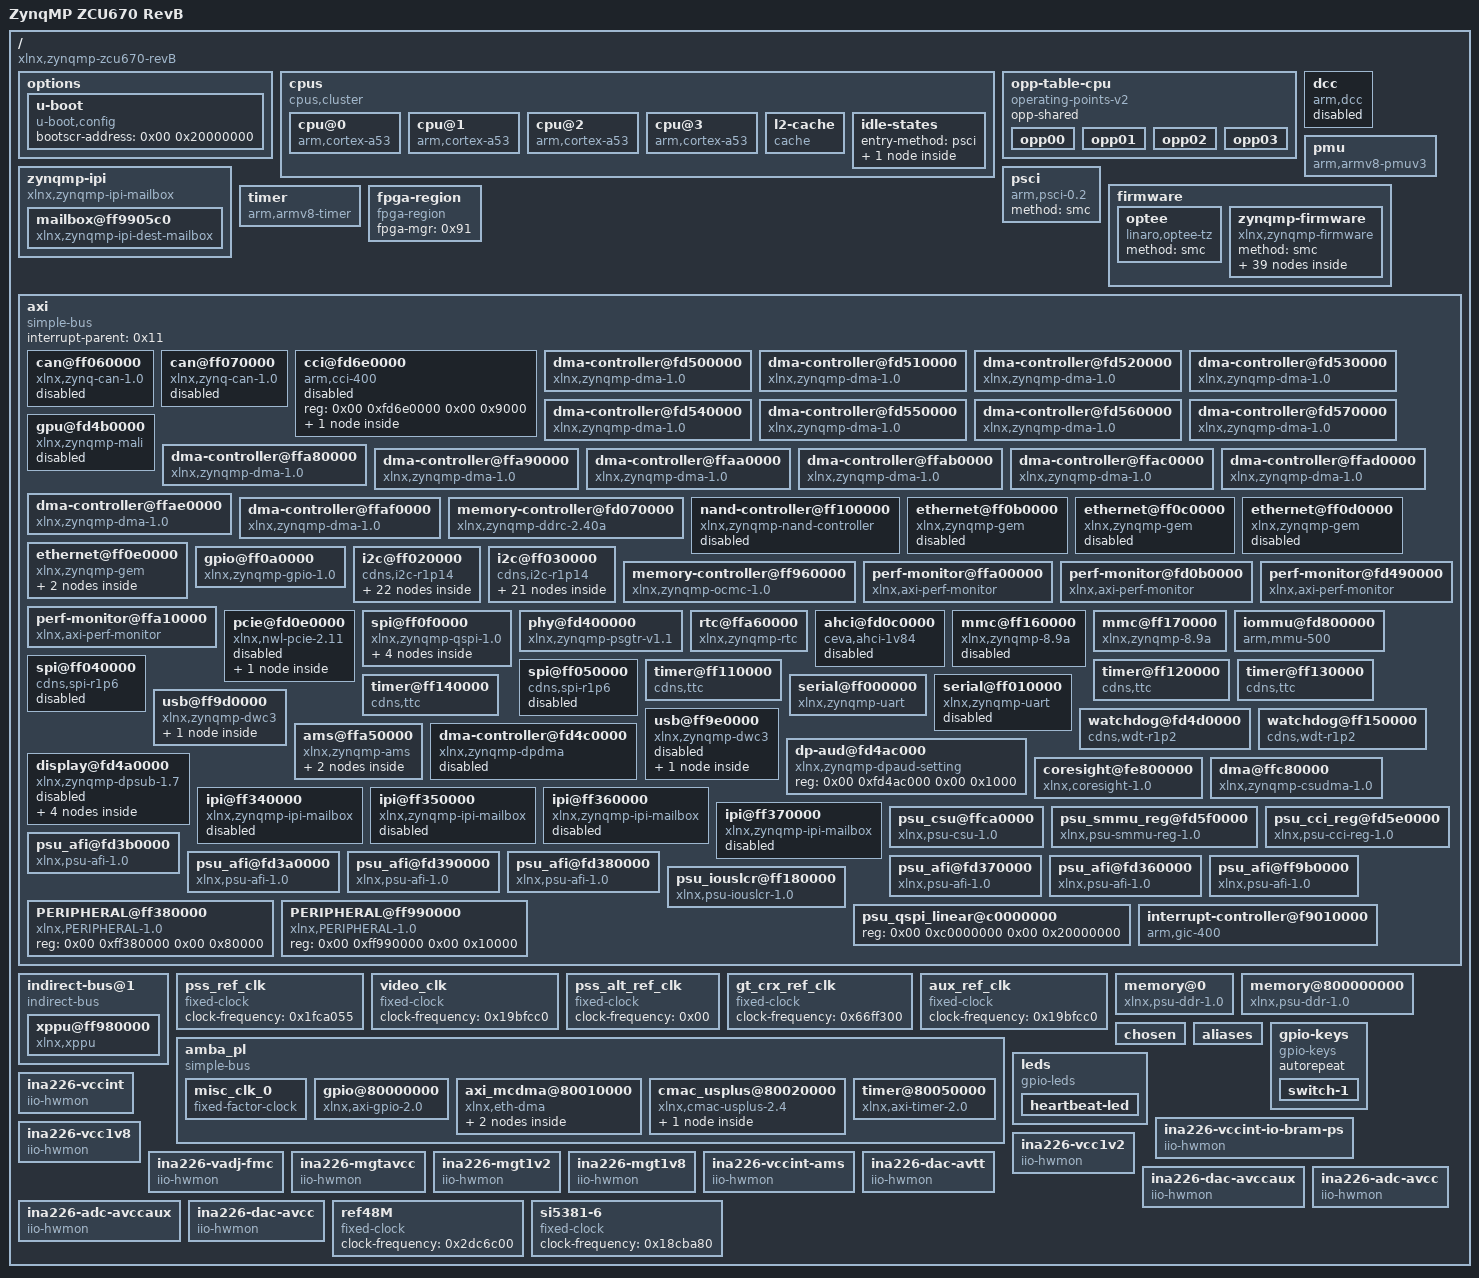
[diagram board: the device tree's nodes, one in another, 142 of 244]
/dts-v1/;

/ {
	compatible = "xlnx,zynqmp-zcu670-revB\0xlnx,zynqmp-zcu670\0xlnx,zynqmp";
	#address-cells = <0x02>;
	#size-cells = <0x02>;
	model = "ZynqMP ZCU670 RevB";
	board = "zcu670";
	device_id = "xczu67dr";
	slrcount = <0x01>;
	family = "ZynqMP";

	options {

		u-boot {
			compatible = "u-boot,config";
			bootscr-address = <0x00 0x20000000>;
		};
	};

	cpus {
		#address-cells = <0x01>;
		#size-cells = <0x00>;
		compatible = "cpus,cluster";
		#ranges-address-cells = <0x02>;
		#ranges-size-cells = <0x02>;
		phandle = <0xb0>;

		cpu@0 {
			compatible = "arm,cortex-a53";
			device_type = "cpu";
			enable-method = "psci";
			operating-points-v2 = <0x6f>;
			reg = <0x00>;
			cpu-idle-states = <0x70>;
			next-level-cache = <0x71>;
			clocks = <0x72 0x0a>;
			xlnx,psu-ep = <0x01>;
			xlnx,pss-video-ref-clk-freq = <0x1fc9f08>;
			xlnx,ip-name = "psu_cortexa53";
			xlnx,cpu-1x-clk-freq-hz = <0x00>;
			xlnx,psu-silicon-version = <0x03>;
			cpu-frequency = <0x47865d45>;
			xlnx,cpu-clk-freq-hz = <0x47865d45>;
			xlnx,pss-gt-ref-clk-freq = <0x1fc9f08>;
			xlnx,pss-ref-clk-freq = <0x1fc9f08>;
			bus-handle = <0x01>;
			xlnx,pss-aux-ref-clk-freq = <0x1fc9f08>;
			xlnx,psu-device = "PS8a";
			xlnx,timestamp-clk-freq = <0x5f5dd19>;
			stamp-frequency = <0x5f5dd19>;
			xlnx,pss-alt-ref-clk-freq = <0x1fc9f08>;
			phandle = <0x87>;
		};

		cpu@1 {
			compatible = "arm,cortex-a53";
			device_type = "cpu";
			enable-method = "psci";
			reg = <0x01>;
			operating-points-v2 = <0x6f>;
			cpu-idle-states = <0x70>;
			next-level-cache = <0x71>;
			xlnx,psu-ep = <0x01>;
			xlnx,ip-name = "psu_cortexa53";
			xlnx,cpu-1x-clk-freq-hz = <0x00>;
			cpu-frequency = <0x47865d45>;
			xlnx,cpu-clk-freq-hz = <0x47865d45>;
			xlnx,psu-silicon-version = <0x03>;
			xlnx,pss-ref-clk-freq = <0x1fc9f08>;
			bus-handle = <0x01>;
			xlnx,psu-device = "PS8a";
			stamp-frequency = <0x5f5dd19>;
			xlnx,timestamp-clk-freq = <0x5f5dd19>;
			phandle = <0x88>;
		};

		cpu@2 {
			compatible = "arm,cortex-a53";
			device_type = "cpu";
			enable-method = "psci";
			reg = <0x02>;
			operating-points-v2 = <0x6f>;
			cpu-idle-states = <0x70>;
			next-level-cache = <0x71>;
			xlnx,psu-ep = <0x01>;
			xlnx,ip-name = "psu_cortexa53";
			xlnx,cpu-1x-clk-freq-hz = <0x00>;
			cpu-frequency = <0x47865d45>;
			xlnx,cpu-clk-freq-hz = <0x47865d45>;
			xlnx,psu-silicon-version = <0x03>;
			xlnx,pss-ref-clk-freq = <0x1fc9f08>;
			bus-handle = <0x01>;
			xlnx,psu-device = "PS8a";
			stamp-frequency = <0x5f5dd19>;
			xlnx,timestamp-clk-freq = <0x5f5dd19>;
			phandle = <0x89>;
		};

		cpu@3 {
			compatible = "arm,cortex-a53";
			device_type = "cpu";
			enable-method = "psci";
			reg = <0x03>;
			operating-points-v2 = <0x6f>;
			cpu-idle-states = <0x70>;
			next-level-cache = <0x71>;
			xlnx,psu-ep = <0x01>;
			xlnx,ip-name = "psu_cortexa53";
			xlnx,cpu-1x-clk-freq-hz = <0x00>;
			cpu-frequency = <0x47865d45>;
			xlnx,cpu-clk-freq-hz = <0x47865d45>;
			xlnx,psu-silicon-version = <0x03>;
			xlnx,pss-ref-clk-freq = <0x1fc9f08>;
			bus-handle = <0x01>;
			xlnx,psu-device = "PS8a";
			stamp-frequency = <0x5f5dd19>;
			xlnx,timestamp-clk-freq = <0x5f5dd19>;
			phandle = <0x8a>;
		};

		l2-cache {
			compatible = "cache";
			cache-level = <0x02>;
			cache-unified;
			phandle = <0x71>;
		};

		idle-states {
			entry-method = "psci";

			cpu-sleep-0 {
				compatible = "arm,idle-state";
				arm,psci-suspend-param = <0x40000000>;
				local-timer-stop;
				entry-latency-us = <0x12c>;
				exit-latency-us = <0x258>;
				min-residency-us = <0x2710>;
				phandle = <0x70>;
			};
		};
	};

	opp-table-cpu {
		compatible = "operating-points-v2";
		opp-shared;
		phandle = <0x6f>;

		opp00 {
			opp-hz = <0x00 0x47868bf4>;
			opp-microvolt = <0xf4240>;
			clock-latency-ns = <0x7a120>;
		};

		opp01 {
			opp-hz = <0x00 0x23c345fa>;
			opp-microvolt = <0xf4240>;
			clock-latency-ns = <0x7a120>;
		};

		opp02 {
			opp-hz = <0x00 0x17d783fc>;
			opp-microvolt = <0xf4240>;
			clock-latency-ns = <0x7a120>;
		};

		opp03 {
			opp-hz = <0x00 0x11e1a2fd>;
			opp-microvolt = <0xf4240>;
			clock-latency-ns = <0x7a120>;
		};
	};

	zynqmp-ipi {
		bootph-all;
		compatible = "xlnx,zynqmp-ipi-mailbox";
		interrupt-parent = <0x11>;
		interrupts = <0x00 0x23 0x04>;
		xlnx,ipi-id = <0x00>;
		#address-cells = <0x02>;
		#size-cells = <0x02>;
		ranges;
		phandle = <0xb7>;

		mailbox@ff9905c0 {
			bootph-all;
			compatible = "xlnx,zynqmp-ipi-dest-mailbox";
			reg = <0x00 0xff9905c0 0x00 0x20 0x00 0xff9905e0 0x00 0x20 0x00 0xff990e80 0x00 0x20 0x00 0xff990ea0 0x00 0x20>;
			reg-names = "local_request_region\0local_response_region\0remote_request_region\0remote_response_region";
			#mbox-cells = <0x01>;
			xlnx,ipi-id = <0x04>;
			phandle = <0x8b>;
		};
	};

	dcc {
		compatible = "arm,dcc";
		status = "disabled";
		bootph-all;
		phandle = <0xb8>;
	};

	pmu {
		compatible = "arm,armv8-pmuv3";
		interrupt-parent = <0x11>;
		interrupts = <0x00 0x8f 0x04 0x00 0x90 0x04 0x00 0x91 0x04 0x00 0x92 0x04>;
		interrupt-affinity = <0x87 0x88 0x89 0x8a>;
	};

	psci {
		compatible = "arm,psci-0.2";
		method = "smc";
	};

	firmware {

		optee {
			compatible = "linaro,optee-tz";
			method = "smc";
			phandle = <0xb9>;
		};

		zynqmp-firmware {
			compatible = "xlnx,zynqmp-firmware";
			#power-domain-cells = <0x01>;
			method = "smc";
			bootph-all;
			phandle = <0x7b>;

			power-management {
				bootph-all;
				compatible = "xlnx,zynqmp-power";
				interrupt-parent = <0x11>;
				interrupts = <0x00 0x23 0x04>;
				mboxes = <0x8b 0x00 0x8b 0x01>;
				mbox-names = "tx\0rx";
				phandle = <0xba>;
			};

			soc-nvmem {
				compatible = "xlnx,zynqmp-nvmem-fw";

				nvmem-layout {
					compatible = "fixed-layout";
					#address-cells = <0x01>;
					#size-cells = <0x01>;

					soc-revision@0 {
						reg = <0x00 0x04>;
						phandle = <0xbb>;
					};

					efuse-dna@c {
						reg = <0x0c 0x0c>;
						phandle = <0xbc>;
					};

					efuse-usr0@20 {
						reg = <0x20 0x04>;
						phandle = <0xbd>;
					};

					efuse-usr1@24 {
						reg = <0x24 0x04>;
						phandle = <0xbe>;
					};

					efuse-usr2@28 {
						reg = <0x28 0x04>;
						phandle = <0xbf>;
					};

					efuse-usr3@2c {
						reg = <0x2c 0x04>;
						phandle = <0xc0>;
					};

					efuse-usr4@30 {
						reg = <0x30 0x04>;
						phandle = <0xc1>;
					};

					efuse-usr5@34 {
						reg = <0x34 0x04>;
						phandle = <0xc2>;
					};

					efuse-usr6@38 {
						reg = <0x38 0x04>;
						phandle = <0xc3>;
					};

					efuse-usr7@3c {
						reg = <0x3c 0x04>;
						phandle = <0xc4>;
					};

					efuse-miscusr@40 {
						reg = <0x40 0x04>;
						phandle = <0xc5>;
					};

					efuse-chash@50 {
						reg = <0x50 0x04>;
						phandle = <0xc6>;
					};

					efuse-pufmisc@54 {
						reg = <0x54 0x04>;
						phandle = <0xc7>;
					};

					efuse-sec@58 {
						reg = <0x58 0x04>;
						phandle = <0xc8>;
					};

					efuse-spkid@5c {
						reg = <0x5c 0x04>;
						phandle = <0xc9>;
					};

					efuse-aeskey@60 {
						reg = <0x60 0x20>;
						phandle = <0xca>;
					};

					efuse-ppk0hash@a0 {
						reg = <0xa0 0x30>;
						phandle = <0xcb>;
					};

					efuse-ppk1hash@d0 {
						reg = <0xd0 0x30>;
						phandle = <0xcc>;
					};

					efuse-pufuser@100 {
						reg = <0x100 0x7f>;
						phandle = <0xcd>;
					};
				};
			};

			pcap {
				compatible = "xlnx,zynqmp-pcap-fpga";
				phandle = <0x91>;
			};

			reset-controller {
				compatible = "xlnx,zynqmp-reset";
				#reset-cells = <0x01>;
				status = "okay";
				phandle = <0x03>;
			};

			pinctrl {
				compatible = "xlnx,zynqmp-pinctrl";
				status = "okay";
				phandle = <0x04>;

				i2c0-default {
					phandle = <0x94>;

					mux {
						groups = "i2c0_3_grp";
						function = "i2c0";
					};

					conf {
						groups = "i2c0_3_grp";
						bias-pull-up;
						slew-rate = <0x01>;
						power-source = <0x01>;
					};
				};

				i2c0-gpio-grp {
					phandle = <0x95>;

					mux {
						groups = "gpio0_14_grp\0gpio0_15_grp";
						function = "gpio0";
					};

					conf {
						groups = "gpio0_14_grp\0gpio0_15_grp";
						slew-rate = <0x01>;
						power-source = <0x01>;
					};
				};

				i2c1-default {
					phandle = <0x96>;

					mux {
						groups = "i2c1_4_grp";
						function = "i2c1";
					};

					conf {
						groups = "i2c1_4_grp";
						bias-pull-up;
						slew-rate = <0x01>;
						power-source = <0x01>;
					};
				};

				i2c1-gpio-grp {
					phandle = <0x97>;

					mux {
						groups = "gpio0_16_grp\0gpio0_17_grp";
						function = "gpio0";
					};

					conf {
						groups = "gpio0_16_grp\0gpio0_17_grp";
						slew-rate = <0x01>;
						power-source = <0x01>;
					};
				};
			};

			gpio {
				compatible = "xlnx,zynqmp-gpio-modepin";
				gpio-controller;
				#gpio-cells = <0x02>;
				phandle = <0x9b>;
			};

			clock-controller {
				bootph-all;
				#clock-cells = <0x01>;
				compatible = "xlnx,zynqmp-clk";
				clocks = <0x8c 0x8d 0x8e 0x8f 0x90>;
				clock-names = "pss_ref_clk\0video_clk\0pss_alt_ref_clk\0aux_ref_clk\0gt_crx_ref_clk";
				phandle = <0x72>;
			};
		};
	};

	timer {
		compatible = "arm,armv8-timer";
		interrupt-parent = <0x11>;
		interrupts = <0x01 0x0d 0xf08 0x01 0x0e 0xf08 0x01 0x0b 0xf08 0x01 0x0a 0xf08>;
	};

	fpga-region {
		compatible = "fpga-region";
		fpga-mgr = <0x91>;
		#address-cells = <0x02>;
		#size-cells = <0x02>;
		ranges;
		phandle = <0xce>;
	};

	axi {
		compatible = "simple-bus";
		bootph-all;
		#address-cells = <0x02>;
		#size-cells = <0x02>;
		ranges;
		interrupt-parent = <0x11>;
		phandle = <0x01>;

		can@ff060000 {
			compatible = "xlnx,zynq-can-1.0";
			status = "disabled";
			clock-names = "can_clk\0pclk";
			reg = <0x00 0xff060000 0x00 0x1000>;
			interrupts = <0x00 0x17 0x04>;
			interrupt-parent = <0x11>;
			tx-fifo-depth = <0x40>;
			rx-fifo-depth = <0x40>;
			resets = <0x03 0x28>;
			power-domains = <0x7b 0x2f>;
			clocks = <0x72 0x3f 0x72 0x1f>;
			phandle = <0xcf>;
		};

		can@ff070000 {
			compatible = "xlnx,zynq-can-1.0";
			status = "disabled";
			clock-names = "can_clk\0pclk";
			reg = <0x00 0xff070000 0x00 0x1000>;
			interrupts = <0x00 0x18 0x04>;
			interrupt-parent = <0x11>;
			tx-fifo-depth = <0x40>;
			rx-fifo-depth = <0x40>;
			resets = <0x03 0x29>;
			power-domains = <0x7b 0x30>;
			clocks = <0x72 0x40 0x72 0x1f>;
			phandle = <0xd0>;
		};

		cci@fd6e0000 {
			compatible = "arm,cci-400";
			status = "disabled";
			reg = <0x00 0xfd6e0000 0x00 0x9000>;
			ranges = <0x00 0x00 0xfd6e0000 0x10000>;
			#address-cells = <0x01>;
			#size-cells = <0x01>;
			phandle = <0xd1>;

			pmu@9000 {
				compatible = "arm,cci-400-pmu,r1";
				reg = <0x9000 0x5000>;
				interrupt-parent = <0x11>;
				interrupts = <0x00 0x7b 0x04 0x00 0x7b 0x04 0x00 0x7b 0x04 0x00 0x7b 0x04 0x00 0x7b 0x04>;
			};
		};

		dma-controller@fd500000 {
			status = "okay";
			compatible = "xlnx,zynqmp-dma-1.0";
			reg = <0x00 0xfd500000 0x00 0x1000>;
			interrupt-parent = <0x11>;
			interrupts = <0x00 0x7c 0x04>;
			clock-names = "clk_main\0clk_apb";
			#dma-cells = <0x01>;
			xlnx,bus-width = <0x80>;
			power-domains = <0x7b 0x2a>;
			clocks = <0x72 0x13 0x72 0x1f>;
			xlnx,ip-name = "psu_gdma";
			xlnx,dma-mode = <0x00>;
			xlnx,dma-type = <0x00>;
			phandle = <0x3f>;
		};

		dma-controller@fd510000 {
			status = "okay";
			compatible = "xlnx,zynqmp-dma-1.0";
			reg = <0x00 0xfd510000 0x00 0x1000>;
			interrupt-parent = <0x11>;
			interrupts = <0x00 0x7d 0x04>;
			clock-names = "clk_main\0clk_apb";
			#dma-cells = <0x01>;
			xlnx,bus-width = <0x80>;
			power-domains = <0x7b 0x2a>;
			clocks = <0x72 0x13 0x72 0x1f>;
			xlnx,ip-name = "psu_gdma";
			xlnx,dma-mode = <0x00>;
			xlnx,dma-type = <0x00>;
			phandle = <0x40>;
		};

		dma-controller@fd520000 {
			status = "okay";
			compatible = "xlnx,zynqmp-dma-1.0";
			reg = <0x00 0xfd520000 0x00 0x1000>;
			interrupt-parent = <0x11>;
			interrupts = <0x00 0x7e 0x04>;
			clock-names = "clk_main\0clk_apb";
			#dma-cells = <0x01>;
			xlnx,bus-width = <0x80>;
			power-domains = <0x7b 0x2a>;
			clocks = <0x72 0x13 0x72 0x1f>;
			xlnx,ip-name = "psu_gdma";
			xlnx,dma-mode = <0x00>;
			xlnx,dma-type = <0x00>;
			phandle = <0x41>;
		};

		dma-controller@fd530000 {
			status = "okay";
			compatible = "xlnx,zynqmp-dma-1.0";
			reg = <0x00 0xfd530000 0x00 0x1000>;
			interrupt-parent = <0x11>;
			interrupts = <0x00 0x7f 0x04>;
			clock-names = "clk_main\0clk_apb";
			#dma-cells = <0x01>;
			xlnx,bus-width = <0x80>;
			power-domains = <0x7b 0x2a>;
			clocks = <0x72 0x13 0x72 0x1f>;
			xlnx,ip-name = "psu_gdma";
			xlnx,dma-mode = <0x00>;
			xlnx,dma-type = <0x00>;
			phandle = <0x42>;
		};

		dma-controller@fd540000 {
			status = "okay";
			compatible = "xlnx,zynqmp-dma-1.0";
			reg = <0x00 0xfd540000 0x00 0x1000>;
			interrupt-parent = <0x11>;
			interrupts = <0x00 0x80 0x04>;
			clock-names = "clk_main\0clk_apb";
			#dma-cells = <0x01>;
			xlnx,bus-width = <0x80>;
			power-domains = <0x7b 0x2a>;
			clocks = <0x72 0x13 0x72 0x1f>;
			xlnx,ip-name = "psu_gdma";
			xlnx,dma-mode = <0x00>;
			xlnx,dma-type = <0x00>;
			phandle = <0x43>;
		};

		dma-controller@fd550000 {
			status = "okay";
			compatible = "xlnx,zynqmp-dma-1.0";
			reg = <0x00 0xfd550000 0x00 0x1000>;
			interrupt-parent = <0x11>;
			interrupts = <0x00 0x81 0x04>;
			clock-names = "clk_main\0clk_apb";
			#dma-cells = <0x01>;
			xlnx,bus-width = <0x80>;
			power-domains = <0x7b 0x2a>;
			clocks = <0x72 0x13 0x72 0x1f>;
			xlnx,ip-name = "psu_gdma";
			xlnx,dma-mode = <0x00>;
			xlnx,dma-type = <0x00>;
			phandle = <0x44>;
		};

		dma-controller@fd560000 {
			status = "okay";
			compatible = "xlnx,zynqmp-dma-1.0";
			reg = <0x00 0xfd560000 0x00 0x1000>;
			interrupt-parent = <0x11>;
			interrupts = <0x00 0x82 0x04>;
			clock-names = "clk_main\0clk_apb";
			#dma-cells = <0x01>;
			xlnx,bus-width = <0x80>;
			power-domains = <0x7b 0x2a>;
			clocks = <0x72 0x13 0x72 0x1f>;
			xlnx,ip-name = "psu_gdma";
			xlnx,dma-mode = <0x00>;
			xlnx,dma-type = <0x00>;
			phandle = <0x45>;
		};

		dma-controller@fd570000 {
			status = "okay";
			compatible = "xlnx,zynqmp-dma-1.0";
			reg = <0x00 0xfd570000 0x00 0x1000>;
			interrupt-parent = <0x11>;
			interrupts = <0x00 0x83 0x04>;
			clock-names = "clk_main\0clk_apb";
			#dma-cells = <0x01>;
			xlnx,bus-width = <0x80>;
			power-domains = <0x7b 0x2a>;
			clocks = <0x72 0x13 0x72 0x1f>;
			xlnx,ip-name = "psu_gdma";
			xlnx,dma-mode = <0x00>;
			xlnx,dma-type = <0x00>;
			phandle = <0x46>;
		};

		gpu@fd4b0000 {
			status = "disabled";
			compatible = "xlnx,zynqmp-mali\0arm,mali-400";
			reg = <0x00 0xfd4b0000 0x00 0x10000>;
			interrupt-parent = <0x11>;
			interrupts = <0x00 0x84 0x04 0x00 0x84 0x04 0x00 0x84 0x04 0x00 0x84 0x04 0x00 0x84 0x04 0x00 0x84 0x04>;
			interrupt-names = "gp\0gpmmu\0pp0\0ppmmu0\0pp1\0ppmmu1";
			clock-names = "bus\0core";
			power-domains = <0x7b 0x3a>;
			clocks = <0x72 0x18 0x72 0x19>;
			phandle = <0xd2>;
		};

		dma-controller@ffa80000 {
			status = "okay";
			compatible = "xlnx,zynqmp-dma-1.0";
			reg = <0x00 0xffa80000 0x00 0x1000>;
			interrupt-parent = <0x11>;
			interrupts = <0x00 0x4d 0x04>;
			clock-names = "clk_main\0clk_apb";
			#dma-cells = <0x01>;
			xlnx,bus-width = <0x40>;
			power-domains = <0x7b 0x2b>;
			clocks = <0x72 0x44 0x72 0x1f>;
			xlnx,is-cache-coherent = <0x00>;
			xlnx,ip-name = "psu_adma";
			xlnx,dma-mode = <0x01>;
			xlnx,dma-type = <0x01>;
			phandle = <0x12>;
		};

		dma-controller@ffa90000 {
			status = "okay";
			compatible = "xlnx,zynqmp-dma-1.0";
			reg = <0x00 0xffa90000 0x00 0x1000>;
			interrupt-parent = <0x11>;
			interrupts = <0x00 0x4e 0x04>;
			clock-names = "clk_main\0clk_apb";
			#dma-cells = <0x01>;
			xlnx,bus-width = <0x40>;
			power-domains = <0x7b 0x2b>;
			clocks = <0x72 0x44 0x72 0x1f>;
			xlnx,is-cache-coherent = <0x00>;
			xlnx,ip-name = "psu_adma";
			xlnx,dma-mode = <0x01>;
			xlnx,dma-type = <0x01>;
			phandle = <0x13>;
		};

		dma-controller@ffaa0000 {
			status = "okay";
			compatible = "xlnx,zynqmp-dma-1.0";
			reg = <0x00 0xffaa0000 0x00 0x1000>;
			interrupt-parent = <0x11>;
			interrupts = <0x00 0x4f 0x04>;
			clock-names = "clk_main\0clk_apb";
			#dma-cells = <0x01>;
			xlnx,bus-width = <0x40>;
			power-domains = <0x7b 0x2b>;
			clocks = <0x72 0x44 0x72 0x1f>;
			xlnx,is-cache-coherent = <0x00>;
			xlnx,ip-name = "psu_adma";
			xlnx,dma-mode = <0x01>;
			xlnx,dma-type = <0x01>;
			phandle = <0x14>;
		};

		dma-controller@ffab0000 {
			status = "okay";
			compatible = "xlnx,zynqmp-dma-1.0";
			reg = <0x00 0xffab0000 0x00 0x1000>;
			interrupt-parent = <0x11>;
			interrupts = <0x00 0x50 0x04>;
			clock-names = "clk_main\0clk_apb";
			#dma-cells = <0x01>;
			xlnx,bus-width = <0x40>;
			power-domains = <0x7b 0x2b>;
			clocks = <0x72 0x44 0x72 0x1f>;
			xlnx,is-cache-coherent = <0x00>;
			xlnx,ip-name = "psu_adma";
			xlnx,dma-mode = <0x01>;
			xlnx,dma-type = <0x01>;
			phandle = <0x15>;
		};

		dma-controller@ffac0000 {
			status = "okay";
			compatible = "xlnx,zynqmp-dma-1.0";
			reg = <0x00 0xffac0000 0x00 0x1000>;
			interrupt-parent = <0x11>;
			interrupts = <0x00 0x51 0x04>;
			clock-names = "clk_main\0clk_apb";
			#dma-cells = <0x01>;
			xlnx,bus-width = <0x40>;
			power-domains = <0x7b 0x2b>;
			clocks = <0x72 0x44 0x72 0x1f>;
			xlnx,is-cache-coherent = <0x00>;
			xlnx,ip-name = "psu_adma";
			xlnx,dma-mode = <0x01>;
			xlnx,dma-type = <0x01>;
			phandle = <0x16>;
		};

		dma-controller@ffad0000 {
			status = "okay";
			compatible = "xlnx,zynqmp-dma-1.0";
			reg = <0x00 0xffad0000 0x00 0x1000>;
			interrupt-parent = <0x11>;
			interrupts = <0x00 0x52 0x04>;
			clock-names = "clk_main\0clk_apb";
			#dma-cells = <0x01>;
			xlnx,bus-width = <0x40>;
			power-domains = <0x7b 0x2b>;
			clocks = <0x72 0x44 0x72 0x1f>;
			xlnx,is-cache-coherent = <0x00>;
			xlnx,ip-name = "psu_adma";
			xlnx,dma-mode = <0x01>;
			xlnx,dma-type = <0x01>;
			phandle = <0x17>;
		};

		dma-controller@ffae0000 {
			status = "okay";
			compatible = "xlnx,zynqmp-dma-1.0";
			reg = <0x00 0xffae0000 0x00 0x1000>;
			interrupt-parent = <0x11>;
			interrupts = <0x00 0x53 0x04>;
			clock-names = "clk_main\0clk_apb";
			#dma-cells = <0x01>;
			xlnx,bus-width = <0x40>;
			power-domains = <0x7b 0x2b>;
			clocks = <0x72 0x44 0x72 0x1f>;
			xlnx,is-cache-coherent = <0x00>;
			xlnx,ip-name = "psu_adma";
			xlnx,dma-mode = <0x01>;
			xlnx,dma-type = <0x01>;
			phandle = <0x18>;
		};

		dma-controller@ffaf0000 {
			status = "okay";
			compatible = "xlnx,zynqmp-dma-1.0";
			reg = <0x00 0xffaf0000 0x00 0x1000>;
			interrupt-parent = <0x11>;
			interrupts = <0x00 0x54 0x04>;
			clock-names = "clk_main\0clk_apb";
			#dma-cells = <0x01>;
			xlnx,bus-width = <0x40>;
			power-domains = <0x7b 0x2b>;
			clocks = <0x72 0x44 0x72 0x1f>;
			xlnx,is-cache-coherent = <0x00>;
			xlnx,ip-name = "psu_adma";
			xlnx,dma-mode = <0x01>;
			xlnx,dma-type = <0x01>;
			phandle = <0x19>;
		};

		memory-controller@fd070000 {
			compatible = "xlnx,zynqmp-ddrc-2.40a";
			reg = <0x00 0xfd070000 0x00 0x30000>;
			interrupt-parent = <0x11>;
			interrupts = <0x00 0x70 0x04>;
			xlnx,bank-addr-bits = <0x02>;
			xlnx,ddrc-parity = <0x00>;
			xlnx,addr-mapping = <0x00>;
			xlnx,has-ecc = <0x00>;
			xlnx,ddr-freq = <0x3e95917d>;
			xlnx,row-addr-bits = <0x10>;
			xlnx,ddrc-low-power-auto-self-refresh = <0x00>;
			xlnx,ip-name = "psu_ddrc";
			xlnx,ddrc-2nd-clock = <0x00>;
			xlnx,brc-mapping = <0x00>;
			xlnx,ddrc-address-copy = <0x00>;
			xlnx,ddrc-data-mask-and-dbi = <0x07>;
			xlnx,ddrc-fine-granularity-refresh-mode = <0x00>;
			xlnx,ddrc-memory-type = <0x04>;
			xlnx,col-addr-bits = <0x0a>;
			xlnx,ddrc-self-refresh-abort = <0x00>;
			xlnx,ddrc-max-operating-temparature = <0x00>;
			status = "okay";
			xlnx,ddrc-address-mirroring = <0x00>;
			xlnx,ddrc-clk-freq-hz = <0x1f4ac8be>;
			xlnx,qos-enable = <0x00>;
			xlnx,ddrc-temp-controlled-refresh = <0x00>;
			xlnx,bg-addr-bits = <0x01>;
			xlnx,ddrc-power-down-enable = <0x00>;
			xlnx,video-buf-size = <0x00>;
			xlnx,ddrc-memory-address-map = <0x00>;
			xlnx,dddrc-ecc = <0x00>;
			xlnx,ddrc-clock-stop = <0x00>;
			xlnx,ddrc-dynamic-ddr-config-enabled = <0x01>;
			phandle = <0x37>;
		};

		nand-controller@ff100000 {
			compatible = "xlnx,zynqmp-nand-controller\0arasan,nfc-v3p10";
			status = "disabled";
			reg = <0x00 0xff100000 0x00 0x1000>;
			clock-names = "controller\0bus";
			interrupt-parent = <0x11>;
			interrupts = <0x00 0x0e 0x04>;
			#address-cells = <0x01>;
			#size-cells = <0x00>;
			power-domains = <0x7b 0x2c>;
			clocks = <0x72 0x3c 0x72 0x1f>;
			phandle = <0xd3>;
		};

		ethernet@ff0b0000 {
			compatible = "xlnx,zynqmp-gem\0cdns,gem";
			status = "disabled";
			interrupt-parent = <0x11>;
			interrupts = <0x00 0x39 0x04 0x00 0x39 0x04>;
			reg = <0x00 0xff0b0000 0x00 0x1000>;
			clock-names = "pclk\0hclk\0tx_clk\0rx_clk\0tsu_clk";
			power-domains = <0x7b 0x1d>;
			resets = <0x03 0x1d>;
			reset-names = "gem0_rst";
			clocks = <0x72 0x1f 0x72 0x68 0x72 0x2d 0x72 0x31 0x72 0x2c>;
			assigned-clocks = <0x72 0x2c>;
			phandle = <0xd4>;
		};

		ethernet@ff0c0000 {
			compatible = "xlnx,zynqmp-gem\0cdns,gem";
			status = "disabled";
			interrupt-parent = <0x11>;
			interrupts = <0x00 0x3b 0x04 0x00 0x3b 0x04>;
			reg = <0x00 0xff0c0000 0x00 0x1000>;
			clock-names = "pclk\0hclk\0tx_clk\0rx_clk\0tsu_clk";
			power-domains = <0x7b 0x1e>;
			resets = <0x03 0x1e>;
			reset-names = "gem1_rst";
			clocks = <0x72 0x1f 0x72 0x69 0x72 0x2e 0x72 0x32 0x72 0x2c>;
			assigned-clocks = <0x72 0x2c>;
			phandle = <0xd5>;
		};

		ethernet@ff0d0000 {
			compatible = "xlnx,zynqmp-gem\0cdns,gem";
			status = "disabled";
			interrupt-parent = <0x11>;
			interrupts = <0x00 0x3d 0x04 0x00 0x3d 0x04>;
			reg = <0x00 0xff0d0000 0x00 0x1000>;
			clock-names = "pclk\0hclk\0tx_clk\0rx_clk\0tsu_clk";
			power-domains = <0x7b 0x1f>;
			resets = <0x03 0x1f>;
			reset-names = "gem2_rst";
			clocks = <0x72 0x1f 0x72 0x6a 0x72 0x2f 0x72 0x33 0x72 0x2c>;
			assigned-clocks = <0x72 0x2c>;
			phandle = <0xd6>;
		};

		ethernet@ff0e0000 {
			compatible = "xlnx,zynqmp-gem\0cdns,gem";
			status = "okay";
			interrupt-parent = <0x11>;
			interrupts = <0x00 0x3f 0x04 0x00 0x3f 0x04>;
			reg = <0x00 0xff0e0000 0x00 0x1000>;
			clock-names = "pclk\0hclk\0tx_clk\0rx_clk\0tsu_clk";
			power-domains = <0x7b 0x20>;
			resets = <0x03 0x20>;
			reset-names = "gem3_rst";
			clocks = <0x72 0x1f 0x72 0x6b 0x72 0x30 0x72 0x34 0x72 0x2c>;
			assigned-clocks = <0x72 0x2c>;
			xlnx,is-cache-coherent = <0x00>;
			xlnx,has-mdio = <0x2faf080>;
			xlnx,gem-board-interface = "custom";
			phy-mode = "rgmii-id";
			xlnx,tz-nonsecure = <0x01>;
			xlnx,enet-slcr-1000mbps-div0 = <0x0c>;
			xlnx,enet-slcr-10mbps-div0 = <0x3c>;
			xlnx,enet-slcr-1000mbps-div1 = <0x01>;
			xlnx,enet-slcr-10mbps-div1 = <0x0a>;
			xlnx,enet-tsu-clk-freq-hz = <0xee6a8ba>;
			xlnx,ip-name = "psu_ethernet";
			xlnx,eth-mode = <0x01>;
			xlnx,enet-reset = <0x2faf080>;
			xlnx,enet-clk-freq-hz = <0x773545d>;
			xlnx,enet-slcr-100mbps-div0 = <0x3c>;
			xlnx,ptp-enet-clock = <0x00>;
			local-mac-address = [ff ff ff ff ff ff];
			xlnx,enet-slcr-100mbps-div1 = <0x01>;
			phy-handle = <0x92>;
			phandle = <0x39>;

			mdio {
				#address-cells = <0x01>;
				#size-cells = <0x00>;
				phandle = <0xd7>;

				ethernet-phy@c {
					#phy-cells = <0x01>;
					compatible = "ethernet-phy-id2000.a231";
					reg = <0x0c>;
					ti,rx-internal-delay = <0x08>;
					ti,tx-internal-delay = <0x0a>;
					ti,fifo-depth = <0x01>;
					ti,dp83867-rxctrl-strap-quirk;
					reset-gpios = <0x93 0x06 0x01>;
					phandle = <0x92>;
				};
			};
		};

		gpio@ff0a0000 {
			compatible = "xlnx,zynqmp-gpio-1.0";
			status = "okay";
			#gpio-cells = <0x02>;
			gpio-controller;
			interrupt-parent = <0x11>;
			interrupts = <0x00 0x10 0x04>;
			interrupt-controller;
			#interrupt-cells = <0x02>;
			reg = <0x00 0xff0a0000 0x00 0x1000>;
			power-domains = <0x7b 0x2e>;
			clocks = <0x72 0x1f>;
			xlnx,gpio-board-interface = "custom";
			xlnx,mio-gpio-mask = <0x5600>;
			gpio-mask-high = <0x00>;
			xlnx,emio-gpio-width = <0x20>;
			xlnx,ip-name = "psu_gpio";
			gpio-mask-low = <0x5600>;
			emio-gpio-width = <0x20>;
			gpio-line-names = "QSPI_LWR_CLK\0QSPI_LWR_DQ1\0QSPI_LWR_DQ2\0QSPI_LWR_DQ3\0QSPI_LWR_DQ0\0QSPI_LWR_CS_B\0\0QSPI_UPR_CS_B\0QSPI_UPR_DQ0\0QSPI_UPR_DQ1\0QSPI_UPR_DQ2\0QSPI_UPR_DQ3\0QSPI_UPR_CLK\0PS_GPIO2\0I2C0_SCL\0I2C0_SDA\0I2C1_SCL\0I2C1_SDA\0UART0_TXD\0UART0_RXD\0\0\0BUTTON\0LED\0\0\0PMU_INPUT\0SFP3_TX_DISABLE\0SFP2_TX_DISABLE\0SFP1_TX_DISABLE\0SFP0_TX_DISABLE\0\0PMU_GPO0\0PMU_GPO1\0PMU_GPO2\0PMU_GPO3\0PMU_GPO4\0PMU_GPO5\0PS_GPIO1\0SDIO_SEL\0SDIO_DIR_CMD\0SDIO_DIR_DAT0\0SDIO_DIR_DAT1\0SD_PWR_RST\0\0SDIO_DETECT\0SDIO_DAT0\0SDIO_DAT1\0SDIO_DAT2\0SDIO_DAT3\0SDIO_CMD\0SDIO_CLK\0USB_CLK\0USB_DIR\0USB_DATA2\0USB_NXT\0USB_DATA0\0USB_DATA1\0USB_STP\0USB_DATA3\0USB_DATA4\0USB_DATA5\0USB_DATA6\0USB_DATA7\0ENET_TX_CLK\0ENET_TX_D0\0ENET_TX_D1\0ENET_TX_D2\0ENET_TX_D3\0ENET_TX_CTRL\0ENET_RX_CLK\0ENET_RX_D0\0ENET_RX_D1\0ENET_RX_D2\0ENET_RX_D3\0ENET_RX_CTRL\0ENET_MDC\0ENET_MDIO\0\0\0\0\0\0\0\0\0\0\0\0\0\0\0\0\0\0\0\0\0\0\0\0\0\0\0\0\0\0\0\0\0\0\0\0\0\0\0\0\0\0\0\0\0\0\0\0\0\0\0\0\0\0\0\0\0\0\0\0\0\0\0\0\0\0\0\0\0\0\0\0\0\0\0\0\0\0\0\0\0\0\0\0\0\0\0\0\0\0\0\0\0\0\0\0";
			phandle = <0x47>;
		};

		i2c@ff020000 {
			compatible = "cdns,i2c-r1p14";
			status = "okay";
			interrupt-parent = <0x11>;
			interrupts = <0x00 0x11 0x04>;
			clock-frequency = <0x61a80>;
			reg = <0x00 0xff020000 0x00 0x1000>;
			#address-cells = <0x01>;
			#size-cells = <0x00>;
			power-domains = <0x7b 0x25>;
			clocks = <0x72 0x3d>;
			xlnx,i2c-reset = <0x00>;
			xlnx,has-interrupt = <0x2faf080>;
			xlnx,clock-freq = <0x5f5dd19>;
			xlnx,i2c-clk-freq-hz = <0x5f5dd19>;
			xlnx,ip-name = "psu_i2c";
			xlnx,iic-board-interface = "custom";
			pinctrl-names = "default\0gpio";
			pinctrl-0 = <0x94>;
			pinctrl-1 = <0x95>;
			scl-gpios = <0x47 0x0e 0x06>;
			sda-gpios = <0x47 0x0f 0x06>;
			phandle = <0x48>;

			gpio@20 {
				compatible = "ti,tca6416";
				reg = <0x20>;
				gpio-controller;
				#gpio-cells = <0x02>;
				gpio-line-names = "MAX6643_OT_B\0MAX6643_FANFAIL_B\0MIO26_PMU_INPUT_LS\0DAC_AVTT_VOUT_SEL\0SI5381_INT_ALM\0IIC_MUX_RESET_B\0GEM3_EXP_RESET_B\0MAX6643_FULL_SPEED\0FMCP_HSPC_PRSNT_M2C_B\0\0\0VCCINT_VRHOT_B\0\08A34001_EXP_RST_B\0IRPS5401_ALERT_B\0INA226_PMBUS_ALERT";
				phandle = <0x93>;
			};

			i2c-mux@75 {
				compatible = "nxp,pca9544";
				#address-cells = <0x01>;
				#size-cells = <0x00>;
				reg = <0x75>;

				i2c@0 {
					#address-cells = <0x01>;
					#size-cells = <0x00>;
					reg = <0x00>;

					ina226@40 {
						compatible = "ti,ina226";
						#io-channel-cells = <0x01>;
						label = "ina226-vccint";
						reg = <0x40>;
						shunt-resistor = <0x1388>;
						phandle = <0xa2>;
					};

					ina226@41 {
						compatible = "ti,ina226";
						#io-channel-cells = <0x01>;
						label = "ina226-vccint-io-bram-ps";
						reg = <0x41>;
						shunt-resistor = <0x1388>;
						phandle = <0xa3>;
					};

					ina226@42 {
						compatible = "ti,ina226";
						#io-channel-cells = <0x01>;
						label = "ina226-vcc1v8";
						reg = <0x42>;
						shunt-resistor = <0x7d0>;
						phandle = <0xa4>;
					};

					ina226@43 {
						compatible = "ti,ina226";
						#io-channel-cells = <0x01>;
						label = "ina226-vcc1v2";
						reg = <0x43>;
						shunt-resistor = <0x1388>;
						phandle = <0xa5>;
					};

					ina226@45 {
						compatible = "ti,ina226";
						#io-channel-cells = <0x01>;
						label = "ina226-vadj-fmc";
						reg = <0x45>;
						shunt-resistor = <0x1388>;
						phandle = <0xa6>;
					};

					ina226@46 {
						compatible = "ti,ina226";
						#io-channel-cells = <0x01>;
						label = "ina226-mgtavcc";
						reg = <0x46>;
						shunt-resistor = <0x7d0>;
						phandle = <0xa7>;
					};

					ina226@47 {
						compatible = "ti,ina226";
						#io-channel-cells = <0x01>;
						label = "ina226-mgt1v2";
						reg = <0x47>;
						shunt-resistor = <0x1388>;
						phandle = <0xa8>;
					};

					ina226@48 {
						compatible = "ti,ina226";
						#io-channel-cells = <0x01>;
						label = "ina226-mgt1v8";
						reg = <0x48>;
						shunt-resistor = <0x1388>;
						phandle = <0xa9>;
					};

					ina226@49 {
						compatible = "ti,ina226";
						#io-channel-cells = <0x01>;
						label = "ina226-vccint-ams";
						reg = <0x49>;
						shunt-resistor = <0x1388>;
						phandle = <0xaa>;
					};

					ina226@4a {
						compatible = "ti,ina226";
						#io-channel-cells = <0x01>;
						label = "ina226-dac-avtt";
						reg = <0x4a>;
						shunt-resistor = <0x1388>;
						phandle = <0xab>;
					};

					ina226@4b {
						compatible = "ti,ina226";
						#io-channel-cells = <0x01>;
						label = "ina226-dac-avccaux";
						reg = <0x4b>;
						shunt-resistor = <0x1388>;
						phandle = <0xac>;
					};

					ina226@4c {
						compatible = "ti,ina226";
						#io-channel-cells = <0x01>;
						label = "ina226-adc-avcc";
						reg = <0x4c>;
						shunt-resistor = <0x1388>;
						phandle = <0xad>;
					};

					ina226@4d {
						compatible = "ti,ina226";
						#io-channel-cells = <0x01>;
						label = "ina226-adc-avccaux";
						reg = <0x4d>;
						shunt-resistor = <0x1388>;
						phandle = <0xae>;
					};

					ina226@4e {
						compatible = "ti,ina226";
						#io-channel-cells = <0x01>;
						label = "ina226-dac-avcc";
						reg = <0x4e>;
						shunt-resistor = <0x1388>;
						phandle = <0xaf>;
					};
				};

				i2c@1 {
					#address-cells = <0x01>;
					#size-cells = <0x00>;
					reg = <0x01>;
				};

				i2c@2 {
					#address-cells = <0x01>;
					#size-cells = <0x00>;
					reg = <0x02>;

					irps5401@44 {
						compatible = "infineon,irps5401";
						reg = <0x44>;
						phandle = <0xd8>;
					};

					irps5401@45 {
						compatible = "infineon,irps5401";
						reg = <0x45>;
						phandle = <0xd9>;
					};
				};

				i2c@3 {
					#address-cells = <0x01>;
					#size-cells = <0x00>;
					reg = <0x03>;
				};
			};
		};

		i2c@ff030000 {
			compatible = "cdns,i2c-r1p14";
			status = "okay";
			interrupt-parent = <0x11>;
			interrupts = <0x00 0x12 0x04>;
			clock-frequency = <0x61a80>;
			reg = <0x00 0xff030000 0x00 0x1000>;
			#address-cells = <0x01>;
			#size-cells = <0x00>;
			power-domains = <0x7b 0x26>;
			clocks = <0x72 0x3e>;
			xlnx,i2c-reset = <0x00>;
			xlnx,has-interrupt = <0x2faf080>;
			xlnx,clock-freq = <0x5f5dd19>;
			xlnx,i2c-clk-freq-hz = <0x5f5dd19>;
			xlnx,ip-name = "psu_i2c";
			xlnx,iic-board-interface = "custom";
			pinctrl-names = "default\0gpio";
			pinctrl-0 = <0x96>;
			pinctrl-1 = <0x97>;
			scl-gpios = <0x47 0x10 0x06>;
			sda-gpios = <0x47 0x11 0x06>;
			phandle = <0x49>;

			i2c-mux@74 {
				compatible = "nxp,pca9548";
				#address-cells = <0x01>;
				#size-cells = <0x00>;
				reg = <0x74>;

				i2c@0 {
					#address-cells = <0x01>;
					#size-cells = <0x00>;
					reg = <0x00>;
					phandle = <0xda>;

					eeprom@54 {
						compatible = "atmel,24c128";
						reg = <0x54>;
						phandle = <0xdb>;
					};
				};

				i2c@1 {
					#address-cells = <0x01>;
					#size-cells = <0x00>;
					reg = <0x01>;
					phandle = <0xdc>;
				};

				i2c@2 {
					#address-cells = <0x01>;
					#size-cells = <0x00>;
					reg = <0x02>;
					phandle = <0xdd>;

					clock-generator@5d {
						#clock-cells = <0x00>;
						compatible = "silabs,si570";
						reg = <0x5d>;
						temperature-stability = <0x32>;
						factory-fout = <0x11e1a300>;
						clock-frequency = <0x11e1a300>;
						clock-output-names = "si570_user_c0";
						phandle = <0xde>;
					};
				};

				i2c@3 {
					#address-cells = <0x01>;
					#size-cells = <0x00>;
					reg = <0x03>;
					phandle = <0xdf>;

					clock-generator@5d {
						#clock-cells = <0x00>;
						compatible = "silabs,si570";
						reg = <0x5d>;
						temperature-stability = <0x32>;
						factory-fout = <0x9502f90>;
						clock-frequency = <0x9502f90>;
						clock-output-names = "si570_mgt";
						phandle = <0xe0>;
					};
				};

				i2c@4 {
					#address-cells = <0x01>;
					#size-cells = <0x00>;
					reg = <0x04>;
					phandle = <0xe1>;
				};

				i2c@5 {
					#address-cells = <0x01>;
					#size-cells = <0x00>;
					reg = <0x05>;
					phandle = <0xe2>;
				};

				i2c@6 {
					#address-cells = <0x01>;
					#size-cells = <0x00>;
					reg = <0x06>;
				};
			};

			i2c-mux@75 {
				compatible = "nxp,pca9548";
				#address-cells = <0x01>;
				#size-cells = <0x00>;
				reg = <0x75>;

				i2c@0 {
					#address-cells = <0x01>;
					#size-cells = <0x00>;
					reg = <0x00>;
				};

				i2c@1 {
					#address-cells = <0x01>;
					#size-cells = <0x00>;
					reg = <0x01>;
					phandle = <0xe3>;

					clock-generator@5d {
						#clock-cells = <0x00>;
						compatible = "silabs,si570";
						reg = <0x5d>;
						temperature-stability = <0x32>;
						factory-fout = <0x1fca055>;
						clock-frequency = <0x1fca055>;
						clock-output-names = "si570_ps_ref_clk";
						silabs,skip-recall;
						phandle = <0xe4>;
					};
				};

				i2c@2 {
					#address-cells = <0x01>;
					#size-cells = <0x00>;
					reg = <0x02>;
				};

				i2c@3 {
					#address-cells = <0x01>;
					#size-cells = <0x00>;
					reg = <0x03>;
				};

				i2c@4 {
					#address-cells = <0x01>;
					#size-cells = <0x00>;
					reg = <0x04>;
				};

				i2c@5 {
					#address-cells = <0x01>;
					#size-cells = <0x00>;
					reg = <0x05>;
				};

				i2c@6 {
					#address-cells = <0x01>;
					#size-cells = <0x00>;
					reg = <0x06>;
				};

				i2c@7 {
					#address-cells = <0x01>;
					#size-cells = <0x00>;
					reg = <0x07>;
				};
			};
		};

		memory-controller@ff960000 {
			compatible = "xlnx,zynqmp-ocmc-1.0";
			reg = <0x00 0xff960000 0x00 0x1000>;
			interrupt-parent = <0x11>;
			interrupts = <0x00 0x0a 0x04>;
			status = "okay";
			xlnx,ip-name = "psu_ocm";
			phandle = <0x54>;
		};

		perf-monitor@ffa00000 {
			compatible = "xlnx,axi-perf-monitor";
			reg = <0x00 0xffa00000 0x00 0x10000>;
			interrupts = <0x00 0x19 0x04>;
			interrupt-parent = <0x11>;
			xlnx,enable-profile = <0x00>;
			xlnx,enable-trace = <0x00>;
			xlnx,num-monitor-slots = <0x01>;
			xlnx,enable-event-count = <0x01>;
			xlnx,enable-event-log = <0x00>;
			xlnx,have-sampled-metric-cnt = <0x01>;
			xlnx,num-of-counters = <0x03>;
			xlnx,metric-count-width = <0x20>;
			xlnx,metrics-sample-count-width = <0x20>;
			xlnx,global-count-width = <0x20>;
			xlnx,metric-count-scale = <0x01>;
			clocks = <0x72 0x1f>;
			xlnx,enable-32bit-filter-id = <0x01>;
			xlnx,ip-name = "psu_apm";
			xlnx,fifo-axis-tid-width = <0x01>;
			xlnx,enable-advanced = <0x01>;
			xlnx,can-clk-freq-hz = <0x2faf080>;
			status = "okay";
			xlnx,fifo-axis-tdata-width = <0x38>;
			xlnx,fifo-axis-depth = <0x20>;
			phandle = <0x23>;
		};

		perf-monitor@fd0b0000 {
			compatible = "xlnx,axi-perf-monitor";
			reg = <0x00 0xfd0b0000 0x00 0x10000>;
			interrupts = <0x00 0x7b 0x04>;
			interrupt-parent = <0x11>;
			xlnx,enable-profile = <0x00>;
			xlnx,enable-trace = <0x00>;
			xlnx,num-monitor-slots = <0x06>;
			xlnx,enable-event-count = <0x01>;
			xlnx,enable-event-log = <0x00>;
			xlnx,have-sampled-metric-cnt = <0x01>;
			xlnx,num-of-counters = <0x0a>;
			xlnx,metric-count-width = <0x20>;
			xlnx,metrics-sample-count-width = <0x20>;
			xlnx,global-count-width = <0x20>;
			xlnx,metric-count-scale = <0x01>;
			clocks = <0x72 0x1c>;
			xlnx,enable-32bit-filter-id = <0x01>;
			xlnx,ip-name = "psu_apm";
			xlnx,fifo-axis-tid-width = <0x01>;
			xlnx,enable-advanced = <0x01>;
			xlnx,can-clk-freq-hz = <0x2faf080>;
			status = "okay";
			xlnx,fifo-axis-tdata-width = <0x38>;
			xlnx,fifo-axis-depth = <0x20>;
			phandle = <0x22>;
		};

		perf-monitor@fd490000 {
			compatible = "xlnx,axi-perf-monitor";
			reg = <0x00 0xfd490000 0x00 0x10000>;
			interrupts = <0x00 0x7b 0x04>;
			interrupt-parent = <0x11>;
			xlnx,enable-profile = <0x00>;
			xlnx,enable-trace = <0x00>;
			xlnx,num-monitor-slots = <0x01>;
			xlnx,enable-event-count = <0x01>;
			xlnx,enable-event-log = <0x00>;
			xlnx,have-sampled-metric-cnt = <0x01>;
			xlnx,num-of-counters = <0x03>;
			xlnx,metric-count-width = <0x20>;
			xlnx,metrics-sample-count-width = <0x20>;
			xlnx,global-count-width = <0x20>;
			xlnx,metric-count-scale = <0x01>;
			clocks = <0x72 0x1c>;
			xlnx,enable-32bit-filter-id = <0x01>;
			xlnx,ip-name = "psu_apm";
			xlnx,fifo-axis-tid-width = <0x01>;
			xlnx,enable-advanced = <0x01>;
			xlnx,can-clk-freq-hz = <0x2faf080>;
			status = "okay";
			xlnx,fifo-axis-tdata-width = <0x38>;
			xlnx,fifo-axis-depth = <0x20>;
			phandle = <0x25>;
		};

		perf-monitor@ffa10000 {
			compatible = "xlnx,axi-perf-monitor";
			reg = <0x00 0xffa10000 0x00 0x10000>;
			interrupts = <0x00 0x19 0x04>;
			interrupt-parent = <0x11>;
			xlnx,enable-profile = <0x00>;
			xlnx,enable-trace = <0x00>;
			xlnx,num-monitor-slots = <0x01>;
			xlnx,enable-event-count = <0x01>;
			xlnx,enable-event-log = <0x00>;
			xlnx,have-sampled-metric-cnt = <0x01>;
			xlnx,num-of-counters = <0x03>;
			xlnx,metric-count-width = <0x20>;
			xlnx,metrics-sample-count-width = <0x20>;
			xlnx,global-count-width = <0x20>;
			xlnx,metric-count-scale = <0x01>;
			clocks = <0x72 0x1f>;
			xlnx,enable-32bit-filter-id = <0x01>;
			xlnx,ip-name = "psu_apm";
			xlnx,fifo-axis-tid-width = <0x01>;
			xlnx,enable-advanced = <0x01>;
			xlnx,can-clk-freq-hz = <0x2faf080>;
			status = "okay";
			xlnx,fifo-axis-tdata-width = <0x38>;
			xlnx,fifo-axis-depth = <0x20>;
			phandle = <0x24>;
		};

		pcie@fd0e0000 {
			compatible = "xlnx,nwl-pcie-2.11";
			status = "disabled";
			#address-cells = <0x03>;
			#size-cells = <0x02>;
			#interrupt-cells = <0x01>;
			msi-controller;
			device_type = "pci";
			interrupt-parent = <0x11>;
			interrupts = <0x00 0x76 0x04 0x00 0x75 0x04 0x00 0x74 0x04 0x00 0x73 0x04 0x00 0x72 0x04>;
			interrupt-names = "misc\0dummy\0intx\0msi1\0msi0";
			msi-parent = <0x98>;
			reg = <0x00 0xfd0e0000 0x00 0x1000 0x00 0xfd480000 0x00 0x1000 0x80 0x00 0x00 0x10000000>;
			reg-names = "breg\0pcireg\0cfg";
			ranges = <0x2000000 0x00 0xe0000000 0x00 0xe0000000 0x00 0x10000000 0x43000000 0x06 0x00 0x06 0x00 0x02 0x00>;
			bus-range = <0x00 0xff>;
			interrupt-map-mask = <0x00 0x00 0x00 0x07>;
			interrupt-map = <0x00 0x00 0x00 0x01 0x99 0x01 0x00 0x00 0x00 0x02 0x99 0x02 0x00 0x00 0x00 0x03 0x99 0x03 0x00 0x00 0x00 0x04 0x99 0x04>;
			power-domains = <0x7b 0x3b>;
			clocks = <0x72 0x17>;
			phandle = <0x98>;

			legacy-interrupt-controller {
				interrupt-controller;
				#address-cells = <0x00>;
				#interrupt-cells = <0x01>;
				phandle = <0x99>;
			};
		};

		spi@ff0f0000 {
			bootph-all;
			compatible = "xlnx,zynqmp-qspi-1.0";
			status = "okay";
			clock-names = "ref_clk\0pclk";
			interrupts = <0x00 0x0f 0x04>;
			interrupt-parent = <0x11>;
			num-cs = <0x02>;
			reg = <0x00 0xff0f0000 0x00 0x1000 0x00 0xc0000000 0x00 0x8000000>;
			#address-cells = <0x01>;
			#size-cells = <0x00>;
			power-domains = <0x7b 0x2d>;
			clocks = <0x72 0x35 0x72 0x1f>;
			xlnx,is-cache-coherent = <0x00>;
			xlnx,tz-nonsecure = <0x01>;
			xlnx,qspi-clk-freq-hz = <0x773545d>;
			xlnx,bus-width = <0x02>;
			xlnx,ip-name = "psu_qspi";
			xlnx,qspi-board-interface = "custom";
			spi-rx-bus-width = <0x04>;
			xlnx,connection-mode = <0x02>;
			spi-tx-bus-width = <0x04>;
			qspi-fbclk = <0x00>;
			xlnx,clock-freq = <0x773545d>;
			xlnx,fb-clk = <0x01>;
			xlnx,qspi-mode = <0x02>;
			is-dual = <0x01>;
			xlnx,qspi-bus-width = <0x02>;
			phandle = <0x57>;

			flash@0 {
				compatible = "m25p80\0jedec,spi-nor";
				#address-cells = <0x01>;
				#size-cells = <0x01>;
				reg = <0x00 0x01>;
				parallel-memories = <0x00 0x10000000 0x00 0x10000000>;
				spi-tx-bus-width = <0x04>;
				spi-rx-bus-width = <0x04>;
				spi-max-frequency = <0x66ff300>;
				phandle = <0x07>;

				partition@0 {
					label = "qspi-boot";
					reg = <0x00 0x2400000>;
				};

				partition@1 {
					label = "qspi-bootenv";
					reg = <0x2400000 0x40000>;
				};

				partition@2 {
					label = "qspi-kernel";
					reg = <0x2440000 0x2400000>;
				};
			};
		};

		phy@fd400000 {
			compatible = "xlnx,zynqmp-psgtr-v1.1";
			status = "okay";
			reg = <0x00 0xfd400000 0x00 0x40000 0x00 0xfd3d0000 0x00 0x1000>;
			reg-names = "serdes\0siou";
			#phy-cells = <0x04>;
			xlnx,ip-name = "psu_serdes";
			clocks = <0x9a>;
			clock-names = "ref2";
			phandle = <0x62>;
		};

		rtc@ffa60000 {
			compatible = "xlnx,zynqmp-rtc";
			status = "okay";
			reg = <0x00 0xffa60000 0x00 0x100>;
			interrupt-parent = <0x11>;
			interrupts = <0x00 0x1a 0x04 0x00 0x1b 0x04>;
			interrupt-names = "alarm\0sec";
			calibration = <0x7fff>;
			xlnx,ip-name = "psu_rtc";
			phandle = <0x60>;
		};

		ahci@fd0c0000 {
			compatible = "ceva,ahci-1v84";
			status = "disabled";
			reg = <0x00 0xfd0c0000 0x00 0x2000>;
			interrupt-parent = <0x11>;
			interrupts = <0x00 0x85 0x04>;
			power-domains = <0x7b 0x1c>;
			resets = <0x03 0x10>;
			clocks = <0x72 0x16>;
			phandle = <0xe5>;
		};

		mmc@ff160000 {
			bootph-all;
			compatible = "xlnx,zynqmp-8.9a\0arasan,sdhci-8.9a";
			status = "disabled";
			interrupt-parent = <0x11>;
			interrupts = <0x00 0x30 0x04>;
			reg = <0x00 0xff160000 0x00 0x1000>;
			clock-names = "clk_xin\0clk_ahb";
			#clock-cells = <0x01>;
			clock-output-names = "clk_out_sd0\0clk_in_sd0";
			power-domains = <0x7b 0x27>;
			resets = <0x03 0x26>;
			clocks = <0x72 0x36 0x72 0x1f>;
			assigned-clocks = <0x72 0x36>;
			phandle = <0xe6>;
		};

		mmc@ff170000 {
			bootph-all;
			compatible = "xlnx,zynqmp-8.9a\0arasan,sdhci-8.9a";
			status = "okay";
			interrupt-parent = <0x11>;
			interrupts = <0x00 0x31 0x04>;
			reg = <0x00 0xff170000 0x00 0x1000>;
			clock-names = "clk_xin\0clk_ahb";
			#clock-cells = <0x01>;
			clock-output-names = "clk_out_sd1\0clk_in_sd1";
			power-domains = <0x7b 0x28>;
			resets = <0x03 0x27>;
			clocks = <0x72 0x37 0x72 0x1f>;
			assigned-clocks = <0x72 0x37>;
			xlnx,sd-board-interface = "custom";
			xlnx,is-cache-coherent = <0x00>;
			xlnx,clk-50-ddr-otap-dly = <0x04>;
			xlnx,clk-50-sdr-itap-dly = <0x28>;
			xlnx,has-emio = <0x00>;
			clock-frequency = <0xb2cfe8b>;
			xlnx,tz-nonsecure = <0x01>;
			xlnx,clk-100-sdr-otap-dly = <0x03>;
			xlnx,mio-bank = <0x01>;
			xlnx,ip-name = "psu_sd";
			xlnx,bus-width = <0x08>;
			xlnx,card-detect = <0x01>;
			xlnx,has-wp = <0x00>;
			xlnx,has-cd = <0x01>;
			xlnx,slot-type = <0x04>;
			xlnx,clk-50-sdr-otap-dly = <0x05>;
			xlnx,clk-50-ddr-itap-dly = <0x33>;
			xlnx,has-power = <0x00>;
			xlnx,clk-200-sdr-otap-dly = <0x03>;
			xlnx,sdio-clk-freq-hz = <0xb2cfe8b>;
			xlnx,write-protect = <0x00>;
			disable-wp;
			no-1-8-v;
			clk-phase-sd-hs = <0x78 0x3c>;
			clk-phase-uhs-sdr25 = <0x84 0x3c>;
			clk-phase-uhs-ddr50 = <0x99 0x30>;
			phandle = <0x61>;
		};

		iommu@fd800000 {
			compatible = "arm,mmu-500";
			reg = <0x00 0xfd800000 0x00 0x20000>;
			#iommu-cells = <0x01>;
			status = "okay";
			#global-interrupts = <0x01>;
			interrupt-parent = <0x11>;
			interrupts = <0x00 0x9b 0x04 0x00 0x9b 0x04 0x00 0x9b 0x04 0x00 0x9b 0x04 0x00 0x9b 0x04 0x00 0x9b 0x04 0x00 0x9b 0x04 0x00 0x9b 0x04 0x00 0x9b 0x04 0x00 0x9b 0x04 0x00 0x9b 0x04 0x00 0x9b 0x04 0x00 0x9b 0x04 0x00 0x9b 0x04 0x00 0x9b 0x04 0x00 0x9b 0x04 0x00 0x9b 0x04>;
			xlnx,ip-name = "psu_smmu_gpv";
			phandle = <0x64>;
		};

		spi@ff040000 {
			compatible = "cdns,spi-r1p6";
			status = "disabled";
			interrupt-parent = <0x11>;
			interrupts = <0x00 0x13 0x04>;
			reg = <0x00 0xff040000 0x00 0x1000>;
			clock-names = "ref_clk\0pclk";
			#address-cells = <0x01>;
			#size-cells = <0x00>;
			power-domains = <0x7b 0x23>;
			clocks = <0x72 0x3a 0x72 0x1f>;
			phandle = <0xe7>;
		};

		spi@ff050000 {
			compatible = "cdns,spi-r1p6";
			status = "disabled";
			interrupt-parent = <0x11>;
			interrupts = <0x00 0x14 0x04>;
			reg = <0x00 0xff050000 0x00 0x1000>;
			clock-names = "ref_clk\0pclk";
			#address-cells = <0x01>;
			#size-cells = <0x00>;
			power-domains = <0x7b 0x24>;
			clocks = <0x72 0x3b 0x72 0x1f>;
			phandle = <0xe8>;
		};

		timer@ff110000 {
			compatible = "cdns,ttc";
			status = "okay";
			interrupt-parent = <0x11>;
			interrupts = <0x00 0x24 0x04 0x00 0x25 0x04 0x00 0x26 0x04>;
			reg = <0x00 0xff110000 0x00 0x1000>;
			timer-width = <0x20>;
			power-domains = <0x7b 0x18>;
			clocks = <0x72 0x1f>;
			xlnx,ttc-board-interface = "custom";
			xlnx,ttc-clk2-freq-hz = <0x5f5e100>;
			xlnx,clock-freq = <0x5f5e100>;
			xlnx,ip-name = "psu_ttc";
			xlnx,ttc-clk0-freq-hz = <0x5f5e100>;
			xlnx,ttc-clk1-freq-hz = <0x5f5e100>;
			phandle = <0x66>;
		};

		timer@ff120000 {
			compatible = "cdns,ttc";
			status = "okay";
			interrupt-parent = <0x11>;
			interrupts = <0x00 0x27 0x04 0x00 0x28 0x04 0x00 0x29 0x04>;
			reg = <0x00 0xff120000 0x00 0x1000>;
			timer-width = <0x20>;
			power-domains = <0x7b 0x19>;
			clocks = <0x72 0x1f>;
			xlnx,ttc-board-interface = "custom";
			xlnx,ttc-clk2-freq-hz = <0x5f5e100>;
			xlnx,clock-freq = <0x5f5e100>;
			xlnx,ip-name = "psu_ttc";
			xlnx,ttc-clk0-freq-hz = <0x5f5e100>;
			xlnx,ttc-clk1-freq-hz = <0x5f5e100>;
			phandle = <0x67>;
		};

		timer@ff130000 {
			compatible = "cdns,ttc";
			status = "okay";
			interrupt-parent = <0x11>;
			interrupts = <0x00 0x2a 0x04 0x00 0x2b 0x04 0x00 0x2c 0x04>;
			reg = <0x00 0xff130000 0x00 0x1000>;
			timer-width = <0x20>;
			power-domains = <0x7b 0x1a>;
			clocks = <0x72 0x1f>;
			xlnx,ttc-board-interface = "custom";
			xlnx,ttc-clk2-freq-hz = <0x5f5e100>;
			xlnx,clock-freq = <0x5f5e100>;
			xlnx,ip-name = "psu_ttc";
			xlnx,ttc-clk0-freq-hz = <0x5f5e100>;
			xlnx,ttc-clk1-freq-hz = <0x5f5e100>;
			phandle = <0x68>;
		};

		timer@ff140000 {
			compatible = "cdns,ttc";
			status = "okay";
			interrupt-parent = <0x11>;
			interrupts = <0x00 0x2d 0x04 0x00 0x2e 0x04 0x00 0x2f 0x04>;
			reg = <0x00 0xff140000 0x00 0x1000>;
			timer-width = <0x20>;
			power-domains = <0x7b 0x1b>;
			clocks = <0x72 0x1f>;
			xlnx,ttc-board-interface = "custom";
			xlnx,ttc-clk2-freq-hz = <0x5f5e100>;
			xlnx,clock-freq = <0x5f5e100>;
			xlnx,ip-name = "psu_ttc";
			xlnx,ttc-clk0-freq-hz = <0x5f5e100>;
			xlnx,ttc-clk1-freq-hz = <0x5f5e100>;
			phandle = <0x69>;
		};

		serial@ff000000 {
			bootph-all;
			compatible = "xlnx,zynqmp-uart\0cdns,uart-r1p12";
			status = "okay";
			interrupt-parent = <0x11>;
			interrupts = <0x00 0x15 0x04>;
			reg = <0x00 0xff000000 0x00 0x1000>;
			clock-names = "uart_clk\0pclk";
			power-domains = <0x7b 0x21>;
			resets = <0x03 0x22>;
			clocks = <0x72 0x38 0x72 0x1f>;
			assigned-clocks = <0x72 0x38>;
			xlnx,has-modem = <0x00>;
			xlnx,uart-clk-freq-hz = <0x5f5dd19>;
			port-number = <0x00>;
			xlnx,ip-name = "psu_uart";
			xlnx,uart-board-interface = "custom";
			xlnx,baudrate = <0x1c200>;
			cts-override;
			u-boot,dm-pre-reloc;
			xlnx,clock-freq = <0x5f5dd19>;
			phandle = <0x6a>;
		};

		serial@ff010000 {
			bootph-all;
			compatible = "xlnx,zynqmp-uart\0cdns,uart-r1p12";
			status = "disabled";
			interrupt-parent = <0x11>;
			interrupts = <0x00 0x16 0x04>;
			reg = <0x00 0xff010000 0x00 0x1000>;
			clock-names = "uart_clk\0pclk";
			power-domains = <0x7b 0x22>;
			resets = <0x03 0x23>;
			clocks = <0x72 0x39 0x72 0x1f>;
			assigned-clocks = <0x72 0x39>;
			phandle = <0xe9>;
		};

		usb@ff9d0000 {
			#address-cells = <0x02>;
			#size-cells = <0x02>;
			status = "okay";
			compatible = "xlnx,zynqmp-dwc3";
			reg = <0x00 0xff9d0000 0x00 0x100>;
			clock-names = "bus_clk\0ref_clk";
			power-domains = <0x7b 0x16>;
			resets = <0x03 0x3b 0x03 0x3d 0x03 0x3f>;
			reset-names = "usb_crst\0usb_hibrst\0usb_apbrst";
			reset-gpios = <0x9b 0x01 0x01>;
			ranges;
			clocks = <0x72 0x20 0x72 0x22>;
			assigned-clocks = <0x72 0x20 0x72 0x22>;
			xlnx,is-cache-coherent = <0x00>;
			xlnx,usb-polarity = <0x00>;
			xlnx,ip-name = "psu_usb";
			xlnx,usb-reset-mode = <0x00>;
			xlnx,usb-board-interface = "custom";
			xlnx,tz-nonsecure = <0x01>;
			phy-names = "usb3-phy";
			phys = <0x62 0x02 0x04 0x00 0x02>;
			phandle = <0x6b>;

			usb@fe200000 {
				compatible = "snps,dwc3";
				status = "okay";
				reg = <0x00 0xfe200000 0x00 0x40000>;
				interrupt-parent = <0x11>;
				interrupt-names = "host\0peripheral\0otg\0wakeup";
				interrupts = <0x00 0x41 0x04 0x00 0x41 0x04 0x00 0x45 0x04 0x00 0x4b 0x04>;
				snps,quirk-frame-length-adjustment = <0x20>;
				clock-names = "ref";
				snps,resume-hs-terminations;
				clocks = <0x72 0x22>;
				xlnx,is-cache-coherent = <0x00>;
				xlnx,ip-name = "psu_usb_xhci";
				xlnx,usb-board-interface = "custom";
				dr_mode = "host";
				snps,usb3_lpm_capable;
				phandle = <0x6c>;
			};
		};

		usb@ff9e0000 {
			#address-cells = <0x02>;
			#size-cells = <0x02>;
			status = "disabled";
			compatible = "xlnx,zynqmp-dwc3";
			reg = <0x00 0xff9e0000 0x00 0x100>;
			clock-names = "bus_clk\0ref_clk";
			power-domains = <0x7b 0x17>;
			resets = <0x03 0x3c 0x03 0x3e 0x03 0x40>;
			reset-names = "usb_crst\0usb_hibrst\0usb_apbrst";
			ranges;
			clocks = <0x72 0x21 0x72 0x22>;
			assigned-clocks = <0x72 0x21 0x72 0x22>;
			phandle = <0xea>;

			usb@fe300000 {
				compatible = "snps,dwc3";
				status = "disabled";
				reg = <0x00 0xfe300000 0x00 0x40000>;
				interrupt-parent = <0x11>;
				interrupt-names = "host\0peripheral\0otg\0wakeup";
				interrupts = <0x00 0x46 0x04 0x00 0x46 0x04 0x00 0x4a 0x04 0x00 0x4c 0x04>;
				snps,quirk-frame-length-adjustment = <0x20>;
				clock-names = "ref";
				snps,resume-hs-terminations;
				clocks = <0x72 0x22>;
				phandle = <0xeb>;
			};
		};

		watchdog@fd4d0000 {
			compatible = "cdns,wdt-r1p2";
			status = "okay";
			interrupt-parent = <0x11>;
			interrupts = <0x00 0x71 0x01>;
			reg = <0x00 0xfd4d0000 0x00 0x1000>;
			timeout-sec = <0x3c>;
			reset-on-timeout;
			clocks = <0x72 0x4b>;
			xlnx,ip-name = "psu_wdt";
			xlnx,wdt-clk-freq-hz = <0x5f5dd19>;
			xlnx,swdt-board-interface = "custom";
			phandle = <0x6e>;
		};

		watchdog@ff150000 {
			compatible = "cdns,wdt-r1p2";
			status = "okay";
			interrupt-parent = <0x11>;
			interrupts = <0x00 0x34 0x01>;
			reg = <0x00 0xff150000 0x00 0x1000>;
			timeout-sec = <0x0a>;
			clocks = <0x72 0x70>;
			xlnx,ip-name = "psu_wdt";
			xlnx,wdt-clk-freq-hz = <0x5f5dd19>;
			xlnx,swdt-board-interface = "custom";
			phandle = <0x6d>;
		};

		ams@ffa50000 {
			compatible = "xlnx,zynqmp-ams";
			status = "okay";
			interrupt-parent = <0x11>;
			interrupts = <0x00 0x38 0x04>;
			reg = <0x00 0xffa50000 0x00 0x800>;
			#address-cells = <0x01>;
			#size-cells = <0x01>;
			#io-channel-cells = <0x01>;
			ranges = <0x00 0x00 0xffa50800 0x800>;
			clocks = <0x72 0x46>;
			xlnx,clock-freq = <0x31>;
			xlnx,ip-name = "psu_ams";
			phandle = <0x21>;

			ams-ps@0 {
				compatible = "xlnx,zynqmp-ams-ps";
				status = "okay";
				reg = <0x00 0x400>;
				phandle = <0x05>;
			};

			ams-pl@400 {
				compatible = "xlnx,zynqmp-ams-pl";
				status = "okay";
				reg = <0x400 0x400>;
				phandle = <0x06>;
			};
		};

		dma-controller@fd4c0000 {
			compatible = "xlnx,zynqmp-dpdma";
			status = "disabled";
			reg = <0x00 0xfd4c0000 0x00 0x1000>;
			interrupts = <0x00 0x7a 0x04>;
			interrupt-parent = <0x11>;
			clock-names = "axi_clk";
			power-domains = <0x7b 0x29>;
			dma-channels = <0x06>;
			#dma-cells = <0x01>;
			clocks = <0x72 0x14>;
			assigned-clocks = <0x72 0x14>;
			phandle = <0x9d>;
		};

		dp-aud@fd4ac000 {
			compatible = "xlnx,zynqmp-dpaud-setting\0syscon";
			reg = <0x00 0xfd4ac000 0x00 0x1000>;
			phandle = <0x9c>;
		};

		display@fd4a0000 {
			bootph-all;
			compatible = "xlnx,zynqmp-dpsub-1.7";
			status = "disabled";
			reg = <0x00 0xfd4a0000 0x00 0x1000 0x00 0xfd4aa000 0x00 0x1000 0x00 0xfd4ab000 0x00 0x1000>;
			reg-names = "dp\0blend\0av_buf";
			xlnx,dpaud-reg = <0x9c>;
			interrupts = <0x00 0x77 0x04>;
			interrupt-parent = <0x11>;
			clock-names = "dp_apb_clk\0dp_aud_clk\0dp_vtc_pixel_clk_in";
			power-domains = <0x7b 0x29>;
			resets = <0x03 0x03>;
			dma-names = "vid0\0vid1\0vid2\0gfx0";
			dmas = <0x9d 0x00 0x9d 0x01 0x9d 0x02 0x9d 0x03>;
			clocks = <0x72 0x1c 0x72 0x11 0x72 0x10>;
			assigned-clocks = <0x72 0x12 0x72 0x11 0x72 0x10>;
			phandle = <0xec>;

			zynqmp-dp-snd-codec0 {
				compatible = "xlnx,dp-snd-codec";
				clock-names = "aud_clk";
				clocks = <0x72 0x11>;
				phandle = <0xa0>;
			};

			zynqmp-dp-snd-pcm0 {
				compatible = "xlnx,dp-snd-pcm0";
				dmas = <0x9d 0x04>;
				dma-names = "tx";
				phandle = <0x9e>;
			};

			zynqmp-dp-snd-pcm1 {
				compatible = "xlnx,dp-snd-pcm1";
				dmas = <0x9d 0x05>;
				dma-names = "tx";
				phandle = <0x9f>;
			};

			zynqmp-dp-snd-card {
				compatible = "xlnx,dp-snd-card";
				xlnx,dp-snd-pcm = <0x9e 0x9f>;
				xlnx,dp-snd-codec = <0xa0>;
				phandle = <0xed>;
			};
		};

		coresight@fe800000 {
			compatible = "xlnx,coresight-1.0";
			status = "okay";
			reg = <0x00 0xfe800000 0x00 0x10000>;
			xlnx,ip-name = "psu_coresight_0";
			phandle = <0x29>;
		};

		dma@ffc80000 {
			status = "okay";
			compatible = "xlnx,zynqmp-csudma-1.0";
			interrupt-parent = <0x11>;
			interrupts = <0x00 0x56 0x04>;
			reg = <0x00 0xffc80000 0x00 0x40000>;
			xlnx,ip-name = "psu_csudma";
			xlnx,dma-type = <0x00>;
			phandle = <0x2d>;
		};

		ipi@ff340000 {
			status = "disabled";
			compatible = "xlnx,zynqmp-ipi-mailbox";
			interrupt-parent = <0x11>;
			interrupts = <0x00 0x1d 0x04>;
			reg = <0x00 0xff340000 0x00 0x20>;
			xlnx,ipi-bitmask = <0x1000000>;
			xlnx,ipi-id = <0x07>;
			xlnx,ipi-buf-index = <0x03>;
			#address-cells = <0x02>;
			#size-cells = <0x02>;
			bootph-all;
			ranges;
			phandle = <0x11f>;
		};

		ipi@ff350000 {
			status = "disabled";
			compatible = "xlnx,zynqmp-ipi-mailbox";
			interrupt-parent = <0x11>;
			interrupts = <0x00 0x1e 0x04>;
			reg = <0x00 0xff350000 0x00 0x20>;
			xlnx,ipi-bitmask = <0x2000000>;
			xlnx,ipi-id = <0x08>;
			xlnx,ipi-buf-index = <0x04>;
			#address-cells = <0x02>;
			#size-cells = <0x02>;
			bootph-all;
			ranges;
			phandle = <0x120>;
		};

		ipi@ff360000 {
			status = "disabled";
			compatible = "xlnx,zynqmp-ipi-mailbox";
			interrupt-parent = <0x11>;
			interrupts = <0x00 0x1f 0x04>;
			reg = <0x00 0xff360000 0x00 0x20>;
			xlnx,ipi-bitmask = <0x4000000>;
			xlnx,ipi-id = <0x09>;
			xlnx,ipi-buf-index = <0x05>;
			#address-cells = <0x02>;
			#size-cells = <0x02>;
			bootph-all;
			ranges;
			phandle = <0x121>;
		};

		ipi@ff370000 {
			status = "disabled";
			compatible = "xlnx,zynqmp-ipi-mailbox";
			interrupt-parent = <0x11>;
			interrupts = <0x00 0x20 0x04>;
			reg = <0x00 0xff370000 0x00 0x20>;
			xlnx,ipi-bitmask = <0x8000000>;
			xlnx,ipi-id = <0x0a>;
			xlnx,ipi-buf-index = <0x05>;
			#address-cells = <0x02>;
			#size-cells = <0x02>;
			bootph-all;
			ranges;
			phandle = <0x122>;
		};

		psu_csu@ffca0000 {
			xlnx,csu-board-interface = "custom";
			compatible = "xlnx,psu-csu-1.0";
			status = "okay";
			xlnx,can-clk-freq-hz = <0xaba9500>;
			xlnx,ip-name = "psu_csu";
			reg = <0x00 0xffca0000 0x00 0x10000>;
			phandle = <0x2c>;
		};

		psu_smmu_reg@fd5f0000 {
			compatible = "xlnx,psu-smmu-reg-1.0";
			status = "okay";
			xlnx,ip-name = "psu_smmu_reg";
			reg = <0x00 0xfd5f0000 0x00 0x10000>;
			phandle = <0x65>;
		};

		psu_cci_reg@fd5e0000 {
			compatible = "xlnx,psu-cci-reg-1.0";
			status = "okay";
			xlnx,ip-name = "psu_cci_reg";
			reg = <0x00 0xfd5e0000 0x00 0x10000>;
			phandle = <0x28>;
		};

		psu_afi@fd3b0000 {
			compatible = "xlnx,psu-afi-1.0";
			status = "okay";
			xlnx,ip-name = "psu_afi";
			reg = <0x00 0xfd3b0000 0x00 0x10000>;
			phandle = <0x1f>;
		};

		psu_afi@fd3a0000 {
			compatible = "xlnx,psu-afi-1.0";
			status = "okay";
			xlnx,ip-name = "psu_afi";
			reg = <0x00 0xfd3a0000 0x00 0x10000>;
			phandle = <0x1e>;
		};

		psu_afi@fd390000 {
			compatible = "xlnx,psu-afi-1.0";
			status = "okay";
			xlnx,ip-name = "psu_afi";
			reg = <0x00 0xfd390000 0x00 0x10000>;
			phandle = <0x1d>;
		};

		psu_afi@fd380000 {
			compatible = "xlnx,psu-afi-1.0";
			status = "okay";
			xlnx,ip-name = "psu_afi";
			reg = <0x00 0xfd380000 0x00 0x10000>;
			phandle = <0x1c>;
		};

		psu_afi@fd370000 {
			compatible = "xlnx,psu-afi-1.0";
			status = "okay";
			xlnx,ip-name = "psu_afi";
			reg = <0x00 0xfd370000 0x00 0x10000>;
			phandle = <0x1b>;
		};

		psu_afi@fd360000 {
			xlnx,is-cache-coherent = <0x00>;
			compatible = "xlnx,psu-afi-1.0";
			status = "okay";
			xlnx,ip-name = "psu_afi";
			reg = <0x00 0xfd360000 0x00 0x10000>;
			phandle = <0x1a>;
		};

		psu_afi@ff9b0000 {
			compatible = "xlnx,psu-afi-1.0";
			status = "okay";
			xlnx,ip-name = "psu_afi";
			reg = <0x00 0xff9b0000 0x00 0x10000>;
			phandle = <0x20>;
		};

		PERIPHERAL@ff380000 {
			compatible = "xlnx,PERIPHERAL-1.0";
			reg = <0x00 0xff380000 0x00 0x80000>;
			phandle = <0x2e>;
		};

		PERIPHERAL@ff990000 {
			compatible = "xlnx,PERIPHERAL-1.0";
			reg = <0x00 0xff990000 0x00 0x10000>;
			phandle = <0x53>;
		};

		psu_iouslcr@ff180000 {
			compatible = "xlnx,psu-iouslcr-1.0";
			status = "okay";
			xlnx,ip-name = "psu_iouslcr";
			reg = <0x00 0xff180000 0x00 0xc0000>;
			phandle = <0x4d>;
		};

		psu_qspi_linear@c0000000 {
			reg = <0x00 0xc0000000 0x00 0x20000000>;
			phandle = <0x129>;
		};

		interrupt-controller@f9010000 {
			phandle = <0x11>;
			xlnx,ip-name = "psu_acpu_gic";
			status = "okay";
			interrupts = <0x01 0x09 0xf04>;
			interrupt-parent = <0x11>;
			interrupt-controller;
			reg = <0x00 0xf9010000 0x00 0x10000 0x00 0xf9020000 0x00 0x20000 0x00 0xf9040000 0x00 0x20000 0x00 0xf9060000 0x00 0x20000>;
			#interrupt-cells = <0x03>;
			compatible = "arm,gic-400";
		};
	};

	indirect-bus@1 {
		compatible = "indirect-bus";
		#address-cells = <0x02>;
		#size-cells = <0x02>;
		phandle = <0x12a>;

		xppu@ff980000 {
			compatible = "xlnx,xppu";
			#firewall-cells = <0x00>;
			reg = <0x00 0xff980000 0x00 0x1000>;
			status = "okay";
			xlnx,ip-name = "psu_lpd_xppu";
			phandle = <0x50>;
		};
	};

	pss_ref_clk {
		bootph-all;
		compatible = "fixed-clock";
		#clock-cells = <0x00>;
		clock-frequency = <0x1fca055>;
		phandle = <0x8c>;
	};

	video_clk {
		bootph-all;
		compatible = "fixed-clock";
		#clock-cells = <0x00>;
		clock-frequency = <0x19bfcc0>;
		phandle = <0x8d>;
	};

	pss_alt_ref_clk {
		bootph-all;
		compatible = "fixed-clock";
		#clock-cells = <0x00>;
		clock-frequency = <0x00>;
		phandle = <0x8e>;
	};

	gt_crx_ref_clk {
		bootph-all;
		compatible = "fixed-clock";
		#clock-cells = <0x00>;
		clock-frequency = <0x66ff300>;
		phandle = <0x90>;
	};

	aux_ref_clk {
		bootph-all;
		compatible = "fixed-clock";
		#clock-cells = <0x00>;
		clock-frequency = <0x19bfcc0>;
		phandle = <0x8f>;
	};

	amba_pl {
		ranges;
		compatible = "simple-bus";
		#address-cells = <0x02>;
		#size-cells = <0x02>;
		firmware-name = "xxv_25g_ptp_subsys_wrapper.bit.bin";
		phandle = <0x12b>;

		misc_clk_0 {
			clock-div = <0x01>;
			compatible = "fixed-factor-clock";
			clock-mult = <0x02>;
			clocks = <0x72 0x47>;
			#clock-cells = <0x00>;
			phandle = <0xa1>;
		};

		gpio@80000000 {
			xlnx,gpio-board-interface = "Custom";
			compatible = "xlnx,axi-gpio-2.0";
			xlnx,all-outputs = <0x00>;
			#gpio-cells = <0x02>;
			xlnx,gpio-width = <0x03>;
			xlnx,dout-default = <0x00>;
			xlnx,is-dual = <0x00>;
			xlnx,ip-name = "axi_gpio";
			xlnx,tri-default-2 = <0xffffffff>;
			reg = <0x00 0x80000000 0x00 0x10000>;
			xlnx,all-inputs-2 = <0x00>;
			clocks = <0x72 0x47>;
			xlnx,all-outputs-2 = <0x00>;
			gpio-controller;
			xlnx,interrupt-present = <0x00>;
			xlnx,gpio2-board-interface = "Custom";
			xlnx,edk-iptype = "PERIPHERAL";
			xlnx,dout-default-2 = <0x00>;
			status = "okay";
			xlnx,gpio2-width = <0x20>;
			clock-names = "s_axi_aclk";
			xlnx,tri-default = <0xffffffff>;
			xlnx,all-inputs = <0x01>;
			phandle = <0x0d>;
		};

		axi_mcdma@80010000 {
			xlnx,group1-s2mm = <0x01>;
			xlnx,mm2s-scheduler = <0x02>;
			xlnx,dlytmr-resolution = <0x7d>;
			xlnx,group4-mm2s = <0x00>;
			xlnx,num-s2mm-channels = <0x01>;
			xlnx,sg-length-width = <0x0e>;
			xlnx,tst-vec = <0x00>;
			xlnx,ip-name = "axi_mcdma";
			reg = <0x00 0x80010000 0x00 0x10000>;
			xlnx,group1-mm2s = <0x01>;
			xlnx,m-axis-mm2s-tdata-width = <0x100>;
			xlnx,sg-use-stsapp-length = <0x00>;
			xlnx,s2mm-burst-size = <0x80>;
			xlnx,num-mm2s-channels = <0x01>;
			xlnx,group6-s2mm = <0x00>;
			xlnx,enable-single-intr = <0x00>;
			interrupt-names = "mm2s_ch1_introut\0s2mm_ch1_introut";
			xlnx,enable-multi-intr = <0x01>;
			compatible = "xlnx,eth-dma";
			xlnx,group3-s2mm = <0x00>;
			xlnx,mm2s-burst-size = <0x80>;
			interrupt-parent = <0x11>;
			xlnx,group6-mm2s = <0x00>;
			xlnx,include-s2mm-dre = <0x01>;
			xlnx,group3-mm2s = <0x00>;
			xlnx,m-axi-s2mm-data-width = <0x100>;
			status = "okay";
			xlnx,include-mm2s-dre = <0x01>;
			interrupts = <0x00 0x59 0x04 0x00 0x5a 0x04>;
			xlnx,m-axi-mm2s-data-width = <0x100>;
			xlnx,group5-s2mm = <0x00>;
			xlnx,include-s2mm-sf = <0x01>;
			xlnx,addr-width = <0x20>;
			xlnx,include-s2mm = <0x01>;
			xlnx,single-interface = <0x00>;
			clocks = <0xa1 0xa1 0x72 0x47 0x72 0x47>;
			xlnx,s-axis-s2mm-tdata-width = <0x100>;
			xlnx,addrwidth = <0x20>;
			xlnx,group2-s2mm = <0x00>;
			xlnx,include-dre;
			xlnx,edk-iptype = "PERIPHERAL";
			xlnx,group5-mm2s = <0x00>;
			xlnx,include-mm2s-sf = <0x01>;
			clock-names = "m_axi_mm2s_aclk\0m_axi_s2mm_aclk\0m_axi_sg_aclk\0s_axi_lite_aclk";
			xlnx,include-mm2s = <0x01>;
			xlnx,s2mm-data-width = <0x100>;
			xlnx,group2-mm2s = <0x00>;
			xlnx,prmry-is-aclk-async = <0x01>;
			#dma-cells = <0x01>;
			xlnx,sg-include-stscntrl-strm = <0x00>;
			xlnx,mm2s-data-width = <0x100>;
			xlnx,group4-s2mm = <0x00>;
			phandle = <0x0e>;
			xlnx,channel-ids = "1";
			xlnx,include-sg;

			dma-channel@80010000 {
				interrupt-parent = <0x11>;
				interrupts = <0x00 0x59 0x04>;
				xlnx,datawidth = <0x100>;
				xlnx,device-id = <0x00>;
				compatible = "xlnx,axi-dma-mm2s-channel";
				xlnx,include-dre;
				dma-channels = <0x01>;
				phandle = <0x12f>;
			};

			dma-channel@80010030 {
				interrupt-parent = <0x11>;
				interrupts = <0x00 0x5a 0x04>;
				xlnx,datawidth = <0x100>;
				xlnx,device-id = <0x00>;
				compatible = "xlnx,axi-dma-s2mm-channel";
				xlnx,include-dre;
				dma-channels = <0x01>;
				phandle = <0x130>;
			};
		};

		cmac_usplus@80020000 {
			xlnx,tx-frame-crc-checking = "Enable , FCS , Insertion";
			xlnx,qpll-fracn-numerator = <0x800000>;
			xlnx,enable-time-stamping = <0x00>;
			xlnx,operating-mode = <0x03>;
			xlnx,rx-ignore-fcs = <0x00>;
			xlnx,include-statistics-counters = <0x01>;
			xlnx,rx-flow-control = <0x01>;
			xlnx,lane2-gt-loc = "X0Y1";
			xlnx,tx-ignore-fcs = <0x01>;
			xlnx,rx-process-lfi = <0x00>;
			xlnx,tx-ethertype-gpp = <0x8808>;
			xlnx,ip-name = "cmac_usplus";
			reg = <0x00 0x80020000 0x00 0x10000>;
			xlnx,enable-axis = <0x00>;
			xlnx,add-gt-cnrl-sts-ports = <0x00>;
			xlnx,include-auto-neg-lt-logic = <0x00>;
			xlnx,line-rate = <0x1896402>;
			xlnx,gt-group-select = <0x00>;
			xlnx,rx-delete-fcs = <0x01>;
			xlnx,enable-axi-interface = <0x01>;
			xlnx,lane1-gt-loc = "X0Y0";
			xlnx,rx-forward-control-frames = <0x00>;
			xlnx,diffclk-board-interface = "Custom";
			xlnx,fast-sim-mode = <0x00>;
			xlnx,tx-sa-ppp = <0x00>;
			xlnx,tx-da-gpp = <0x00>;
			compatible = "xlnx,cmac-usplus-2.4";
			xlnx,gt-type = "GTY";
			xlnx,rx-opcode-gpp = <0x01>;
			xlnx,rx-pause-sa = <0x00>;
			xlnx,tx-opcode-gpp = <0x01>;
			xlnx,exdes-axi4lite-interface = <0x00>;
			xlnx,tx-ptp-vlane-adjust-mode = <0x00>;
			xlnx,rx-check-preamble = <0x00>;
			xlnx,rx-etype-gpp = <0x8808>;
			xlnx,include-shared-logic = <0x02>;
			xlnx,rx-pause-da-mcast = <0x00>;
			xlnx,family-chk = "zynquplus";
			xlnx,rx-max-packet-len = <0x2580>;
			status = "okay";
			xlnx,use-board-flow;
			xlnx,pll-type = "QPLL0";
			xlnx,rs-fec-transcode-bypass = <0x00>;
			xlnx,tx-fcs-ins-enable = <0x01>;
			xlnx,tx-ethertype-ppp = <0x8808>;
			xlnx,tx-lane0-vlm-bip7-override = <0x00>;
			xlnx,rx-opcode-min-gcp = <0x00>;
			xlnx,rx-opcode-max-gcp = <0xffff>;
			xlnx,rx-pause-da-ucast = <0x00>;
			xlnx,clocking-mode = "Asynchronous";
			xlnx,is-board-project = <0x01>;
			xlnx,enable-pipeline-reg = <0x00>;
			xlnx,ptp-transpclk-mode = <0x00>;
			xlnx,rx-etype-gcp = <0x8808>;
			xlnx,tx-flow-control = <0x01>;
			xlnx,gt-ref-clk-freq = <0x9502f90>;
			xlnx,update-lt-coeff = <0x00>;
			xlnx,gt-rx-buffer-bypass = <0x00>;
			xlnx,include-an-lt-tx-trainer = <0x00>;
			xlnx,num-lanes = <0x04>;
			clocks = <0x72 0x47 0xa1 0x72 0x47>;
			xlnx,cmac-caui4-mode = <0x01>;
			xlnx,gt-location = <0x01>;
			xlnx,rx-check-ack = <0x00>;
			xlnx,tx-da-ppp = <0x00>;
			xlnx,edk-iptype = "PERIPHERAL";
			xlnx,rx-min-packet-len = <0x40>;
			xlnx,user-interface = "AXIS";
			xlnx,ins-loss-nyq = <0x0c>;
			xlnx,rx-opcode-ppp = <0x101>;
			clock-names = "s_axi_aclk\0rx_core_clk\0dclk";
			xlnx,rx-check-sfd = <0x00>;
			xlnx,tx-opcode-ppp = <0x101>;
			xlnx,ethernet-board-interface = "Custom";
			xlnx,tx-ptp-latency-adjust = <0x00>;
			xlnx,rx-etype-ppp = <0x8808>;
			xlnx,gt-drp-clk = <0x64>;
			xlnx,cmac-core-select = "CMACE4_X0Y0";
			xlnx,lane4-gt-loc = "X0Y3";
			xlnx,rs-fec-core-sel = "CMACE4_X0Y0";
			xlnx,statistics-regs-type = <0x00>;
			xlnx,tx-sa-gpp = <0x00>;
			xlnx,include-rs-fec = <0x01>;
			xlnx,rx-opcode-min-pcp = <0x00>;
			xlnx,tx-ptp-1step-enable = <0x00>;
			xlnx,tx-ipg-value = <0x0c>;
			xlnx,rx-opcode-max-pcp = <0xffff>;
			xlnx,lane3-gt-loc = "X0Y2";
			xlnx,rx-etype-pcp = <0x8808>;
			xlnx,rx-eq-mode = "AUTO";
			xlnx,tx-otn-interface = <0x00>;
			xlnx,rx-frame-crc-checking = "Enable , FCS , Stripping";
			xlnx,rx-gt-buffer = <0x01>;
			phandle = <0x0f>;
			axistream-connected = <0x0e>;
			axigpio-handle = <0x0d>;
			xlnx,channel-ids = "1";
			local-mac-address = [00 0a 35 00 00 01];
			xlnx,include-dre;
			interrupts = <0x00 0x59 0x04 0x00 0x5a 0x04>;
			interrupt-names = "mm2s_ch1_introut\0s2mm_ch1_introut";
			interrupt-parent = <0x11>;
			xlnx,num-queues = [00 01];
			xlnx,addrwidth = <0x20>;
			phy-handle = <0x02>;
			phy-mode = "100gbase-cr4";

			fixed-link {
				compatible = "fixed-link";
				speed = <0x186a0>;
				full-duplex;
				phandle = <0x02>;
			};
		};

		timer@80050000 {
			interrupts = <0x00 0x5b 0x04>;
			compatible = "xlnx,axi-timer-2.0\0xlnx,xps-timer-1.00.a";
			xlnx,gen1-assert = <0x01>;
			clock-frequency = <0x94590d1>;
			xlnx,trig0-assert = <0x01>;
			interrupt-parent = <0x11>;
			xlnx,count-width = <0x20>;
			xlnx,ip-name = "axi_timer";
			xlnx,one-timer-only = <0x00>;
			reg = <0x00 0x80050000 0x00 0x10000>;
			clocks = <0x72 0x47>;
			xlnx,gen0-assert = <0x01>;
			xlnx,mode-64bit = <0x00>;
			xlnx,edk-iptype = "PERIPHERAL";
			status = "okay";
			xlnx,trig1-assert = <0x01>;
			clock-names = "s_axi_aclk";
			xlnx,enable-timer2 = <0x01>;
			interrupt-names = "interrupt";
			phandle = <0x10>;
		};
	};

	memory@0 {
		compatible = "xlnx,psu-ddr-1.0";
		xlnx,ip-name = "psu_ddr";
		device_type = "memory";
		memory_type = "memory";
		reg = <0x00 0x00 0x00 0x7ff00000>;
		phandle = <0x0b>;
	};

	memory@800000000 {
		compatible = "xlnx,psu-ddr-1.0";
		xlnx,ip-name = "psu_ddr";
		device_type = "memory";
		memory_type = "memory";
		reg = <0x08 0x00 0x00 0x80000000>;
		phandle = <0x0c>;
	};

	chosen {
		bootargs = "earlycon console=ttyPS0,115200 root=/dev/ram0 rw";
		stdout-path = "serial0:115200n8";
	};

	aliases {
		serial0 = "/axi/serial@ff000000";
		spi0 = "/axi/spi@ff0f0000";
		serial1 = "/dcc";
		i2c0 = "/axi/i2c@ff020000";
		i2c1 = "/axi/i2c@ff030000";
		ethernet0 = "/axi/ethernet@ff0e0000";
		mmc0 = "/axi/mmc@ff170000";
		nvmem0 = "/axi/i2c@ff030000/i2c-mux@74/i2c@0/eeprom@54";
		rtc0 = "/axi/rtc@ffa60000";
		usb0 = "/axi/usb@ff9d0000";
	};

	gpio-keys {
		compatible = "gpio-keys";
		autorepeat;

		switch-1 {
			label = "sw1";
			gpios = <0x47 0x16 0x00>;
			linux,code = <0x100>;
			wakeup-source;
			autorepeat;
		};
	};

	leds {
		compatible = "gpio-leds";

		heartbeat-led {
			label = "heartbeat";
			gpios = <0x47 0x17 0x00>;
			linux,default-trigger = "heartbeat";
		};
	};

	ina226-vccint {
		compatible = "iio-hwmon";
		io-channels = <0xa2 0x00 0xa2 0x01 0xa2 0x02 0xa2 0x03>;
	};

	ina226-vccint-io-bram-ps {
		compatible = "iio-hwmon";
		io-channels = <0xa3 0x00 0xa3 0x01 0xa3 0x02 0xa3 0x03>;
	};

	ina226-vcc1v8 {
		compatible = "iio-hwmon";
		io-channels = <0xa4 0x00 0xa4 0x01 0xa4 0x02 0xa4 0x03>;
	};

	ina226-vcc1v2 {
		compatible = "iio-hwmon";
		io-channels = <0xa5 0x00 0xa5 0x01 0xa5 0x02 0xa5 0x03>;
	};

	ina226-vadj-fmc {
		compatible = "iio-hwmon";
		io-channels = <0xa6 0x00 0xa6 0x01 0xa6 0x02 0xa6 0x03>;
	};

	ina226-mgtavcc {
		compatible = "iio-hwmon";
		io-channels = <0xa7 0x00 0xa7 0x01 0xa7 0x02 0xa7 0x03>;
	};

	ina226-mgt1v2 {
		compatible = "iio-hwmon";
		io-channels = <0xa8 0x00 0xa8 0x01 0xa8 0x02 0xa8 0x03>;
	};

	ina226-mgt1v8 {
		compatible = "iio-hwmon";
		io-channels = <0xa9 0x00 0xa9 0x01 0xa9 0x02 0xa9 0x03>;
	};

	ina226-vccint-ams {
		compatible = "iio-hwmon";
		io-channels = <0xaa 0x00 0xaa 0x01 0xaa 0x02 0xaa 0x03>;
	};

	ina226-dac-avtt {
		compatible = "iio-hwmon";
		io-channels = <0xab 0x00 0xab 0x01 0xab 0x02 0xab 0x03>;
	};

	ina226-dac-avccaux {
		compatible = "iio-hwmon";
		io-channels = <0xac 0x00 0xac 0x01 0xac 0x02 0xac 0x03>;
	};

	ina226-adc-avcc {
		compatible = "iio-hwmon";
		io-channels = <0xad 0x00 0xad 0x01 0xad 0x02 0xad 0x03>;
	};

	ina226-adc-avccaux {
		compatible = "iio-hwmon";
		io-channels = <0xae 0x00 0xae 0x01 0xae 0x02 0xae 0x03>;
	};

	ina226-dac-avcc {
		compatible = "iio-hwmon";
		io-channels = <0xaf 0x00 0xaf 0x01 0xaf 0x02 0xaf 0x03>;
	};

	ref48M {
		compatible = "fixed-clock";
		#clock-cells = <0x00>;
		clock-frequency = <0x2dc6c00>;
		phandle = <0x131>;
	};

	si5381-6 {
		compatible = "fixed-clock";
		#clock-cells = <0x00>;
		clock-frequency = <0x18cba80>;
		phandle = <0x9a>;
	};

	__symbols__ {
		cpus_a53 = "/cpus-a53@0";
		psu_cortexa53_0 = "/cpus-a53@0/cpu@0";
		psu_cortexa53_1 = "/cpus-a53@0/cpu@1";
		psu_cortexa53_2 = "/cpus-a53@0/cpu@2";
		psu_cortexa53_3 = "/cpus-a53@0/cpu@3";
		L2 = "/cpus-a53@0/l2-cache";
		CPU_SLEEP_0 = "/cpus-a53@0/idle-states/cpu-sleep-0";
		cpu_opp_table = "/opp-table-cpu";
		zynqmp_ipi = "/zynqmp-ipi";
		ipi_mailbox_pmu1 = "/zynqmp-ipi/mailbox@ff9905c0";
		dcc = "/dcc";
		optee = "/firmware/optee";
		zynqmp_firmware = "/firmware/zynqmp-firmware";
		zynqmp_power = "/firmware/zynqmp-firmware/power-management";
		soc_revision = "/firmware/zynqmp-firmware/soc-nvmem/nvmem-layout/soc-revision@0";
		efuse_dna = "/firmware/zynqmp-firmware/soc-nvmem/nvmem-layout/efuse-dna@c";
		efuse_usr0 = "/firmware/zynqmp-firmware/soc-nvmem/nvmem-layout/efuse-usr0@20";
		efuse_usr1 = "/firmware/zynqmp-firmware/soc-nvmem/nvmem-layout/efuse-usr1@24";
		efuse_usr2 = "/firmware/zynqmp-firmware/soc-nvmem/nvmem-layout/efuse-usr2@28";
		efuse_usr3 = "/firmware/zynqmp-firmware/soc-nvmem/nvmem-layout/efuse-usr3@2c";
		efuse_usr4 = "/firmware/zynqmp-firmware/soc-nvmem/nvmem-layout/efuse-usr4@30";
		efuse_usr5 = "/firmware/zynqmp-firmware/soc-nvmem/nvmem-layout/efuse-usr5@34";
		efuse_usr6 = "/firmware/zynqmp-firmware/soc-nvmem/nvmem-layout/efuse-usr6@38";
		efuse_usr7 = "/firmware/zynqmp-firmware/soc-nvmem/nvmem-layout/efuse-usr7@3c";
		efuse_miscusr = "/firmware/zynqmp-firmware/soc-nvmem/nvmem-layout/efuse-miscusr@40";
		efuse_chash = "/firmware/zynqmp-firmware/soc-nvmem/nvmem-layout/efuse-chash@50";
		efuse_pufmisc = "/firmware/zynqmp-firmware/soc-nvmem/nvmem-layout/efuse-pufmisc@54";
		efuse_sec = "/firmware/zynqmp-firmware/soc-nvmem/nvmem-layout/efuse-sec@58";
		efuse_spkid = "/firmware/zynqmp-firmware/soc-nvmem/nvmem-layout/efuse-spkid@5c";
		efuse_aeskey = "/firmware/zynqmp-firmware/soc-nvmem/nvmem-layout/efuse-aeskey@60";
		efuse_ppk0hash = "/firmware/zynqmp-firmware/soc-nvmem/nvmem-layout/efuse-ppk0hash@a0";
		efuse_ppk1hash = "/firmware/zynqmp-firmware/soc-nvmem/nvmem-layout/efuse-ppk1hash@d0";
		efuse_pufuser = "/firmware/zynqmp-firmware/soc-nvmem/nvmem-layout/efuse-pufuser@100";
		zynqmp_pcap = "/firmware/zynqmp-firmware/pcap";
		zynqmp_reset = "/firmware/zynqmp-firmware/reset-controller";
		pinctrl0 = "/firmware/zynqmp-firmware/pinctrl";
		pinctrl_i2c0_default = "/firmware/zynqmp-firmware/pinctrl/i2c0-default";
		pinctrl_i2c0_gpio = "/firmware/zynqmp-firmware/pinctrl/i2c0-gpio-grp";
		pinctrl_i2c1_default = "/firmware/zynqmp-firmware/pinctrl/i2c1-default";
		pinctrl_i2c1_gpio = "/firmware/zynqmp-firmware/pinctrl/i2c1-gpio-grp";
		modepin_gpio = "/firmware/zynqmp-firmware/gpio";
		zynqmp_clk = "/firmware/zynqmp-firmware/clock-controller";
		fpga_full = "/fpga-region";
		amba_apu = "/apu-bus";
		amba = "/axi";
		imux = "/axi/interrupt-multiplex";
		can0 = "/axi/can@ff060000";
		can1 = "/axi/can@ff070000";
		cci = "/axi/cci@fd6e0000";
		fpd_dma_chan1 = "/axi/dma-controller@fd500000";
		fpd_dma_chan2 = "/axi/dma-controller@fd510000";
		fpd_dma_chan3 = "/axi/dma-controller@fd520000";
		fpd_dma_chan4 = "/axi/dma-controller@fd530000";
		fpd_dma_chan5 = "/axi/dma-controller@fd540000";
		fpd_dma_chan6 = "/axi/dma-controller@fd550000";
		fpd_dma_chan7 = "/axi/dma-controller@fd560000";
		fpd_dma_chan8 = "/axi/dma-controller@fd570000";
		gpu = "/axi/gpu@fd4b0000";
		lpd_dma_chan1 = "/axi/dma-controller@ffa80000";
		lpd_dma_chan2 = "/axi/dma-controller@ffa90000";
		lpd_dma_chan3 = "/axi/dma-controller@ffaa0000";
		lpd_dma_chan4 = "/axi/dma-controller@ffab0000";
		lpd_dma_chan5 = "/axi/dma-controller@ffac0000";
		lpd_dma_chan6 = "/axi/dma-controller@ffad0000";
		lpd_dma_chan7 = "/axi/dma-controller@ffae0000";
		lpd_dma_chan8 = "/axi/dma-controller@ffaf0000";
		mc = "/axi/memory-controller@fd070000";
		nand0 = "/axi/nand-controller@ff100000";
		gem0 = "/axi/ethernet@ff0b0000";
		gem1 = "/axi/ethernet@ff0c0000";
		gem2 = "/axi/ethernet@ff0d0000";
		gem3 = "/axi/ethernet@ff0e0000";
		mdio = "/axi/ethernet@ff0e0000/mdio";
		phy0 = "/axi/ethernet@ff0e0000/mdio/ethernet-phy@c";
		gpio = "/axi/gpio@ff0a0000";
		i2c0 = "/axi/i2c@ff020000";
		tca6416_u15 = "/axi/i2c@ff020000/gpio@20";
		vccint = "/axi/i2c@ff020000/i2c-mux@75/i2c@0/ina226@40";
		vccint_io_bram_ps = "/axi/i2c@ff020000/i2c-mux@75/i2c@0/ina226@41";
		vcc1v8 = "/axi/i2c@ff020000/i2c-mux@75/i2c@0/ina226@42";
		vcc1v2 = "/axi/i2c@ff020000/i2c-mux@75/i2c@0/ina226@43";
		vadj_fmc = "/axi/i2c@ff020000/i2c-mux@75/i2c@0/ina226@45";
		mgtavcc = "/axi/i2c@ff020000/i2c-mux@75/i2c@0/ina226@46";
		mgt1v2 = "/axi/i2c@ff020000/i2c-mux@75/i2c@0/ina226@47";
		mgt1v8 = "/axi/i2c@ff020000/i2c-mux@75/i2c@0/ina226@48";
		vccint_ams = "/axi/i2c@ff020000/i2c-mux@75/i2c@0/ina226@49";
		dac_avtt = "/axi/i2c@ff020000/i2c-mux@75/i2c@0/ina226@4a";
		dac_avccaux = "/axi/i2c@ff020000/i2c-mux@75/i2c@0/ina226@4b";
		adc_avcc = "/axi/i2c@ff020000/i2c-mux@75/i2c@0/ina226@4c";
		adc_avccaux = "/axi/i2c@ff020000/i2c-mux@75/i2c@0/ina226@4d";
		dac_avcc = "/axi/i2c@ff020000/i2c-mux@75/i2c@0/ina226@4e";
		irps5401_44 = "/axi/i2c@ff020000/i2c-mux@75/i2c@2/irps5401@44";
		irps5401_45 = "/axi/i2c@ff020000/i2c-mux@75/i2c@2/irps5401@45";
		i2c1 = "/axi/i2c@ff030000";
		i2c_eeprom = "/axi/i2c@ff030000/i2c-mux@74/i2c@0";
		eeprom = "/axi/i2c@ff030000/i2c-mux@74/i2c@0/eeprom@54";
		i2c_si5381 = "/axi/i2c@ff030000/i2c-mux@74/i2c@1";
		i2c_si570_user_c0 = "/axi/i2c@ff030000/i2c-mux@74/i2c@2";
		si570_1 = "/axi/i2c@ff030000/i2c-mux@74/i2c@2/clock-generator@5d";
		i2c_si570_mgt = "/axi/i2c@ff030000/i2c-mux@74/i2c@3";
		si570_2 = "/axi/i2c@ff030000/i2c-mux@74/i2c@3/clock-generator@5d";
		i2c_8a34001 = "/axi/i2c@ff030000/i2c-mux@74/i2c@4";
		i2c_clk104 = "/axi/i2c@ff030000/i2c-mux@74/i2c@5";
		i2c_si570_psrefclk = "/axi/i2c@ff030000/i2c-mux@75/i2c@1";
		si570_3 = "/axi/i2c@ff030000/i2c-mux@75/i2c@1/clock-generator@5d";
		ocm = "/axi/memory-controller@ff960000";
		perf_monitor_ocm = "/axi/perf-monitor@ffa00000";
		perf_monitor_ddr = "/axi/perf-monitor@fd0b0000";
		perf_monitor_cci = "/axi/perf-monitor@fd490000";
		perf_monitor_lpd = "/axi/perf-monitor@ffa10000";
		pcie = "/axi/pcie@fd0e0000";
		pcie_intc = "/axi/pcie@fd0e0000/legacy-interrupt-controller";
		qspi = "/axi/spi@ff0f0000";
		psgtr = "/axi/phy@fd400000";
		rtc = "/axi/rtc@ffa60000";
		sata = "/axi/ahci@fd0c0000";
		sdhci0 = "/axi/mmc@ff160000";
		sdhci1 = "/axi/mmc@ff170000";
		smmu = "/axi/iommu@fd800000";
		spi0 = "/axi/spi@ff040000";
		spi1 = "/axi/spi@ff050000";
		ttc0 = "/axi/timer@ff110000";
		ttc1 = "/axi/timer@ff120000";
		ttc2 = "/axi/timer@ff130000";
		ttc3 = "/axi/timer@ff140000";
		uart0 = "/axi/serial@ff000000";
		uart1 = "/axi/serial@ff010000";
		usb0 = "/axi/usb@ff9d0000";
		dwc3_0 = "/axi/usb@ff9d0000/usb@fe200000";
		usb1 = "/axi/usb@ff9e0000";
		dwc3_1 = "/axi/usb@ff9e0000/usb@fe300000";
		watchdog0 = "/axi/watchdog@fd4d0000";
		lpd_watchdog = "/axi/watchdog@ff150000";
		xilinx_ams = "/axi/ams@ffa50000";
		ams_ps = "/axi/ams@ffa50000/ams-ps@0";
		ams_pl = "/axi/ams@ffa50000/ams-pl@400";
		zynqmp_dpdma = "/axi/dma-controller@fd4c0000";
		zynqmp_dpaud_setting = "/axi/dp-aud@fd4ac000";
		zynqmp_dpsub = "/axi/display@fd4a0000";
		zynqmp_dp_snd_codec0 = "/axi/display@fd4a0000/zynqmp-dp-snd-codec0";
		zynqmp_dp_snd_pcm0 = "/axi/display@fd4a0000/zynqmp-dp-snd-pcm0";
		zynqmp_dp_snd_pcm1 = "/axi/display@fd4a0000/zynqmp-dp-snd-pcm1";
		zynqmp_dp_snd_card0 = "/axi/display@fd4a0000/zynqmp-dp-snd-card";
		coresight_0 = "/axi/coresight@fe800000";
		csudma_0 = "/axi/dma@ffc80000";
		ipi7 = "/axi/ipi@ff340000";
		ipi8 = "/axi/ipi@ff350000";
		ipi9 = "/axi/ipi@ff360000";
		ipi10 = "/axi/ipi@ff370000";
		psu_csu_0 = "/axi/psu_csu@ffca0000";
		psu_smmu_reg = "/axi/psu_smmu_reg@fd5f0000";
		psu_cci_reg = "/axi/psu_cci_reg@fd5e0000";
		psu_afi_5 = "/axi/psu_afi@fd3b0000";
		psu_afi_4 = "/axi/psu_afi@fd3a0000";
		psu_afi_3 = "/axi/psu_afi@fd390000";
		psu_afi_2 = "/axi/psu_afi@fd380000";
		psu_afi_1 = "/axi/psu_afi@fd370000";
		psu_afi_0 = "/axi/psu_afi@fd360000";
		psu_afi_6 = "/axi/psu_afi@ff9b0000";
		psu_ctrl_ipi = "/axi/PERIPHERAL@ff380000";
		psu_message_buffers = "/axi/PERIPHERAL@ff990000";
		psu_iouslcr_0 = "/axi/psu_iouslcr@ff180000";
		psu_qspi_linear_0 = "/axi/psu_qspi_linear@c0000000";
		amba_xppu = "/indirect-bus@1";
		lpd_xppu = "/indirect-bus@1/xppu@ff980000";
		pss_ref_clk = "/pss_ref_clk";
		video_clk = "/video_clk";
		pss_alt_ref_clk = "/pss_alt_ref_clk";
		gt_crx_ref_clk = "/gt_crx_ref_clk";
		aux_ref_clk = "/aux_ref_clk";
		amba_pl = "/amba_pl";
		misc_clk_0 = "/amba_pl/misc_clk_0";
		cmac_axi_gpio_0 = "/amba_pl/gpio@80000000";
		cmac_axi_mcdma_0 = "/amba_pl/axi_mcdma@80010000";
		dma_channel_80010000 = "/amba_pl/axi_mcdma@80010000/dma-channel@80010000";
		dma_channel_80010030 = "/amba_pl/axi_mcdma@80010000/dma-channel@80010030";
		cmac_cmac_usplus_0 = "/amba_pl/cmac_usplus@80020000";
		other_perph_axi_timer_1 = "/amba_pl/timer@80050000";
		psu_ddr_0_memory = "/memory@0";
		psu_ddr_1_memory = "/memory@800000000";
		ref48 = "/ref48M";
		si5381_6 = "/si5381-6";
		gic = "/axi/interrupt-controller@f9010000";
		flash0 = "/axi/spi@ff0f0000/flash@0";
		fixed_link_100g = "/amba_pl/cmac_usplus@80020000/fixed-link";
	};
};
